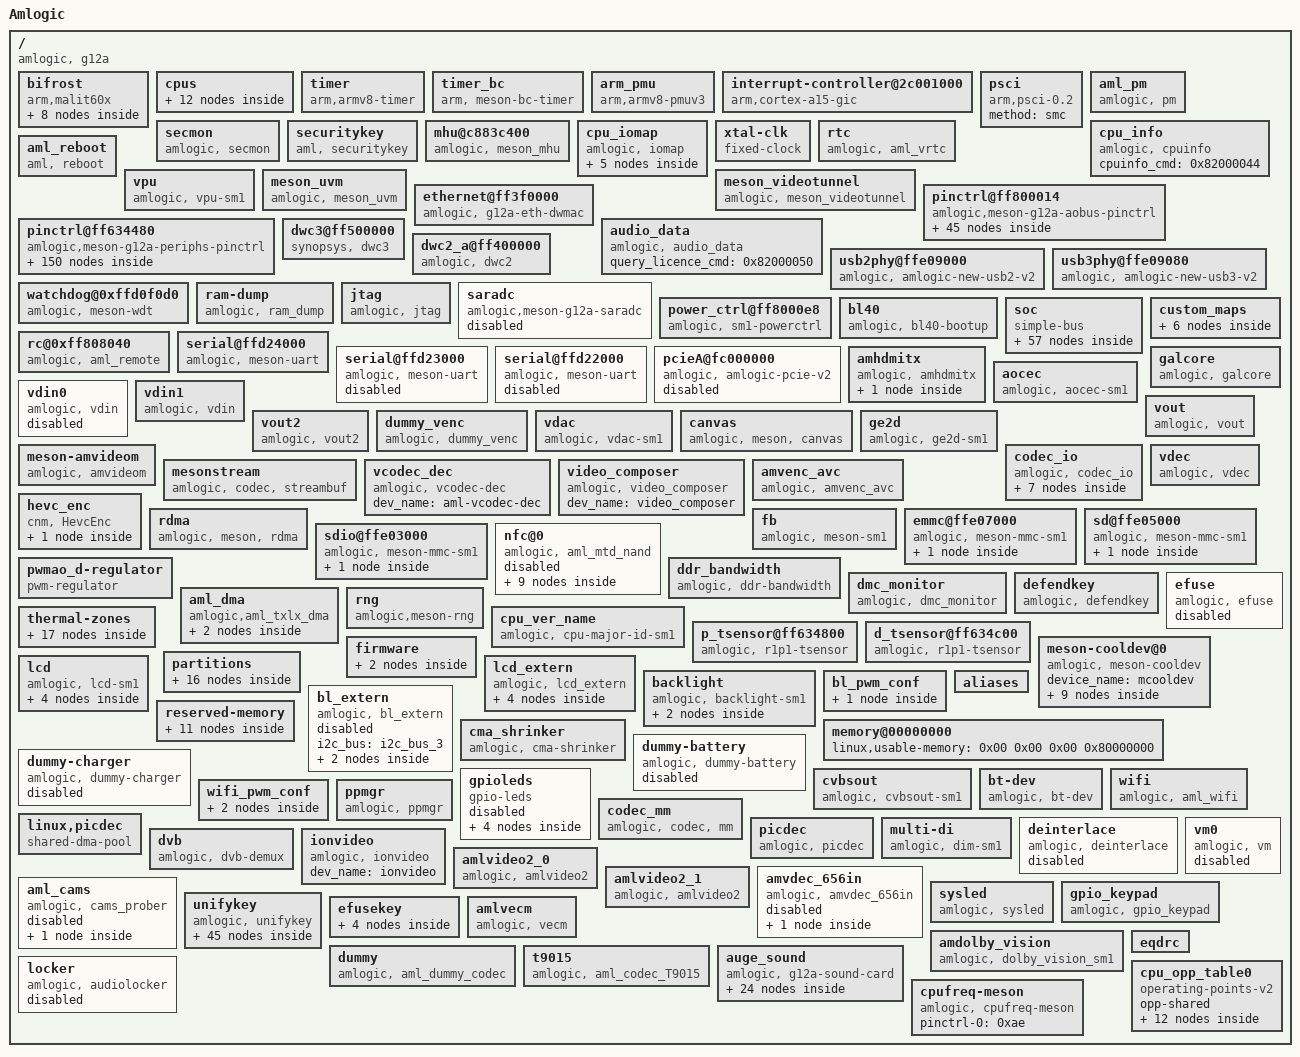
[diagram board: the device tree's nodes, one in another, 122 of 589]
/dts-v1/;

/ {
	model = "Amlogic";
	amlogic-dt-id = "sm1_ac214_2g";
	compatible = "amlogic, g12a";
	interrupt-parent = <0x01>;
	#address-cells = <0x02>;
	#size-cells = <0x02>;

	bifrost {
		compatible = "arm,malit60x\0arm,malit6xx\0arm,mali-midgard";
		#cooling-cells = <0x02>;
		reg = <0x00 0xffe40000 0x00 0x4000 0x00 0xffd01000 0x00 0x1000 0x00 0xff800000 0x00 0x1000 0x00 0xff63c000 0x00 0x1000 0x00 0xffd01000 0x00 0x1000>;
		interrupt-parent = <0x01>;
		interrupts = <0x00 0xa0 0x04 0x00 0xa1 0x04 0x00 0xa2 0x04>;
		interrupt-names = "GPU\0MMU\0JOB";
		num_of_pp = <0x02>;
		sc_mpp = <0x01>;
		clocks = <0x02 0x83 0x02 0x07>;
		clock-names = "gpu_mux\0gp0_pll";
		tbl = <0x03 0x04 0x05 0x06 0x07 0x07>;
		phandle = <0xaf>;

		clk125_cfg {
			clk_freq = <0x7735940>;
			clk_parent = "fclk_div4";
			clkp_freq = <0x1dcd6500>;
			clk_reg = <0xa03>;
			voltage = <0x47e>;
			keep_count = <0x05>;
			threshold = <0x1e 0x78>;
			phandle = <0xb0>;
		};

		dvfs250_cfg {
			clk_freq = <0xee6b280>;
			clk_parent = "fclk_div4";
			clkp_freq = <0x1dcd6500>;
			clk_reg = <0xa01>;
			voltage = <0x47e>;
			keep_count = <0x05>;
			threshold = <0x50 0xaa>;
			phandle = <0xb1>;
		};

		dvfs285_cfg {
			clk_freq = <0x1107a76d>;
			clk_parent = "fclk_div7";
			clkp_freq = <0x1107a76d>;
			clk_reg = <0xe00>;
			voltage = <0x47e>;
			keep_count = <0x05>;
			threshold = <0x00 0x4c>;
			phandle = <0x03>;
		};

		dvfs400_cfg {
			clk_freq = <0x17d78400>;
			clk_parent = "fclk_div5";
			clkp_freq = <0x17d78400>;
			clk_reg = <0xc00>;
			voltage = <0x47e>;
			keep_count = <0x05>;
			threshold = <0x98 0xcf>;
			phandle = <0x04>;
		};

		dvfs500_cfg {
			clk_freq = <0x1dcd6500>;
			clk_parent = "fclk_div4";
			clkp_freq = <0x1dcd6500>;
			clk_reg = <0xa00>;
			voltage = <0x47e>;
			keep_count = <0x05>;
			threshold = <0x26 0xc2>;
			phandle = <0x05>;
		};

		dvfs666_cfg {
			clk_freq = <0x27bc86aa>;
			clk_parent = "fclk_div3";
			clkp_freq = <0x27bc86aa>;
			clk_reg = <0x800>;
			voltage = <0x47e>;
			keep_count = <0x05>;
			threshold = <0x96 0xcb>;
			phandle = <0x06>;
		};

		dvfs800_cfg {
			clk_freq = <0x2faf0800>;
			clk_parent = "fclk_div2p5";
			clkp_freq = <0x2faf0800>;
			clk_reg = <0x600>;
			voltage = <0x47e>;
			keep_count = <0x05>;
			threshold = <0xe6 0xff>;
			phandle = <0xb2>;
		};

		dvfs850_cfg {
			clk_freq = <0x326cef80>;
			clk_parent = "gp0_pll";
			clkp_freq = <0x326cef80>;
			clk_reg = <0x200>;
			voltage = <0x47e>;
			keep_count = <0x05>;
			threshold = <0x9c 0xff>;
			phandle = <0x07>;
		};
	};

	cpus {
		#address-cells = <0x02>;
		#size-cells = <0x00>;
		phandle = <0xb3>;

		cpu-map {

			cluster0 {
				phandle = <0xb4>;

				core0 {
					cpu = <0x08>;
				};

				core1 {
					cpu = <0x09>;
				};

				core2 {
					cpu = <0x0a>;
				};

				core3 {
					cpu = <0x0b>;
				};
			};
		};

		cpu@0 {
			device_type = "cpu";
			compatible = "arm,cortex-a53\0arm,armv8";
			reg = <0x00 0x00>;
			enable-method = "psci";
			cpu-idle-states = <0x0c>;
			clocks = <0x02 0x17 0x02 0x16 0x02 0x00 0x02 0xf8 0x02 0xf7>;
			clock-names = "core_clk\0low_freq_clk_parent\0high_freq_clk_parent\0dsu_clk\0dsu_pre_parent";
			operating-points-v2 = <0x0d>;
			cpu-supply = <0x0e>;
			voltage-tolerance = <0x00>;
			clock-latency = <0xc350>;
			phandle = <0x08>;
		};

		cpu@1 {
			device_type = "cpu";
			compatible = "arm,cortex-a53\0arm,armv8";
			reg = <0x00 0x01>;
			enable-method = "psci";
			cpu-idle-states = <0x0c>;
			clocks = <0x02 0x17 0x02 0x16 0x02 0x00 0x02 0xf8 0x02 0xf7>;
			clock-names = "core_clk\0low_freq_clk_parent\0high_freq_clk_parent\0dsu_clk\0dsu_pre_parent";
			operating-points-v2 = <0x0d>;
			cpu-supply = <0x0e>;
			voltage-tolerance = <0x00>;
			clock-latency = <0xc350>;
			phandle = <0x09>;
		};

		cpu@2 {
			device_type = "cpu";
			compatible = "arm,cortex-a53\0arm,armv8";
			reg = <0x00 0x02>;
			enable-method = "psci";
			cpu-idle-states = <0x0c>;
			clocks = <0x02 0x17 0x02 0x16 0x02 0x00 0x02 0xf8 0x02 0xf7>;
			clock-names = "core_clk\0low_freq_clk_parent\0high_freq_clk_parent\0dsu_clk\0dsu_pre_parent";
			operating-points-v2 = <0x0d>;
			cpu-supply = <0x0e>;
			voltage-tolerance = <0x00>;
			clock-latency = <0xc350>;
			phandle = <0x0a>;
		};

		cpu@3 {
			device_type = "cpu";
			compatible = "arm,cortex-a53\0arm,armv8";
			reg = <0x00 0x03>;
			enable-method = "psci";
			cpu-idle-states = <0x0c>;
			clocks = <0x02 0x17 0x02 0x16 0x02 0x00 0x02 0xf8 0x02 0xf7>;
			clock-names = "core_clk\0low_freq_clk_parent\0high_freq_clk_parent\0dsu_clk\0dsu_pre_parent";
			operating-points-v2 = <0x0d>;
			cpu-supply = <0x0e>;
			voltage-tolerance = <0x00>;
			clock-latency = <0xc350>;
			phandle = <0x0b>;
		};

		idle-states {
			entry-method = "arm,psci-0.2";

			cpu-sleep-0 {
				compatible = "arm,idle-state";
				arm,psci-suspend-param = <0x10000>;
				local-timer-stop;
				entry-latency-us = <0xfa0>;
				exit-latency-us = <0x1388>;
				min-residency-us = <0x2710>;
				phandle = <0x0c>;
			};
		};
	};

	timer {
		compatible = "arm,armv8-timer";
		interrupts = <0x01 0x0d 0xff08 0x01 0x0e 0xff08 0x01 0x0b 0xff08 0x01 0x0a 0xff08>;
	};

	timer_bc {
		compatible = "arm, meson-bc-timer";
		reg = <0x00 0xffd0f190 0x00 0x04 0x00 0xffd0f194 0x00 0x04>;
		timer_name = "Meson TimerF";
		clockevent-rating = <0x12c>;
		clockevent-shift = <0x14>;
		clockevent-features = <0x23>;
		interrupts = <0x00 0x3c 0x01>;
		bit_enable = <0x10>;
		bit_mode = <0x0c>;
		bit_resolution = <0x00>;
	};

	arm_pmu {
		compatible = "arm,armv8-pmuv3";
		interrupts = <0x00 0x89 0x04>;
		reg = <0x00 0xff634680 0x00 0x04>;
		cpumasks = <0x0f>;
		relax-timer-ns = <0x989680>;
		max-wait-cnt = <0x2710>;
	};

	interrupt-controller@2c001000 {
		compatible = "arm,cortex-a15-gic\0arm,cortex-a9-gic";
		#interrupt-cells = <0x03>;
		#address-cells = <0x00>;
		interrupt-controller;
		reg = <0x00 0xffc01000 0x00 0x1000 0x00 0xffc02000 0x00 0x100>;
		interrupts = <0x01 0x09 0xf04>;
		phandle = <0x01>;
	};

	psci {
		compatible = "arm,psci-0.2";
		method = "smc";
	};

	aml_pm {
		compatible = "amlogic, pm";
		status = "okay";
		device_name = "aml_pm";
		debug_reg = <0xff8000a8>;
		exit_reg = <0xff80023c>;
	};

	secmon {
		compatible = "amlogic, secmon";
		memory-region = <0x0f>;
		in_base_func = <0x82000020>;
		out_base_func = <0x82000021>;
		reserve_mem_size = <0x300000>;
	};

	securitykey {
		compatible = "aml, securitykey";
		storage_query = <0x82000060>;
		storage_read = <0x82000061>;
		storage_write = <0x82000062>;
		storage_tell = <0x82000063>;
		storage_verify = <0x82000064>;
		storage_status = <0x82000065>;
		storage_list = <0x82000067>;
		storage_remove = <0x82000068>;
		storage_in_func = <0x82000023>;
		storage_out_func = <0x82000024>;
		storage_block_func = <0x82000025>;
		storage_size_func = <0x82000027>;
		storage_set_enctype = <0x8200006a>;
		storage_get_enctype = <0x8200006b>;
		storage_version = <0x8200006c>;
	};

	mhu@c883c400 {
		compatible = "amlogic, meson_mhu";
		reg = <0x00 0xff63c400 0x00 0x4c 0x00 0xfffe7000 0x00 0x800>;
		interrupts = <0x00 0xd1 0x01 0x00 0xd2 0x01 0x00 0xd5 0x01>;
		#mbox-cells = <0x01>;
		mbox-names = "cpu_to_scp_low\0bl4_to_cpu\0cpu_to_bl4";
		mboxes = <0x10 0x00 0x10 0x01 0x10 0x02>;
		num-chans-to-scp = <0x01>;
		send-isr-bits = <0x05>;
		ack-isr-bits = <0x04>;
		m4-isr-bits = <0x06>;
		mbox-chans = <0x03>;
		phandle = <0x10>;
	};

	cpu_iomap {
		compatible = "amlogic, iomap";
		#address-cells = <0x02>;
		#size-cells = <0x02>;
		ranges;

		io_cbus_base {
			reg = <0x00 0xffd00000 0x00 0x26fff>;
		};

		io_apb_base {
			reg = <0x00 0xffe01000 0x00 0x7f000>;
		};

		io_aobus_base {
			reg = <0x00 0xff800000 0x00 0xb000>;
		};

		io_vapb_base {
			reg = <0x00 0xff900000 0x00 0x50000>;
		};

		io_hiu_base {
			reg = <0x00 0xff63c000 0x00 0x2000>;
		};
	};

	xtal-clk {
		compatible = "fixed-clock";
		clock-frequency = <0x16e3600>;
		clock-output-names = "xtal";
		#clock-cells = <0x00>;
		phandle = <0x14>;
	};

	rtc {
		compatible = "amlogic, aml_vrtc";
		alarm_reg_addr = <0xff8000a8>;
		timer_e_addr = <0xffd0f188>;
		init_date = "2015/01/01";
		status = "okay";
	};

	cpu_info {
		compatible = "amlogic, cpuinfo";
		status = "okay";
		cpuinfo_cmd = <0x82000044>;
	};

	aml_reboot {
		compatible = "aml, reboot";
		sys_reset = <0x84000009>;
		sys_poweroff = <0x84000008>;
	};

	vpu {
		compatible = "amlogic, vpu-sm1";
		dev_name = "vpu";
		status = "okay";
		clocks = <0x02 0x95 0x02 0x4c 0x02 0x87 0x02 0x8b 0x02 0x8c>;
		clock-names = "vapb_clk\0vpu_intr_gate\0vpu_clk0\0vpu_clk1\0vpu_clk";
		clk_level = <0x07>;
		phandle = <0xb5>;
	};

	meson_uvm {
		compatible = "amlogic, meson_uvm";
		status = "okay";
	};

	meson_videotunnel {
		compatible = "amlogic, meson_videotunnel";
		status = "okay";
	};

	ethernet@ff3f0000 {
		compatible = "amlogic, g12a-eth-dwmac\0snps,dwmac";
		reg = <0x00 0xff3f0000 0x00 0x10000 0x00 0xff634540 0x00 0x08 0x00 0xff64c000 0x00 0xa0 0x00 0xffd01008 0x00 0x04>;
		reg-names = "eth_base\0eth_cfg\0eth_pll\0eth_reset";
		interrupts = <0x00 0x08 0x01>;
		interrupt-names = "macirq";
		status = "okay";
		clocks = <0x02 0x38>;
		clock-names = "ethclk81";
		pll_val = <0x9c0040a 0x927e0000 0xac5f49e5>;
		analog_val = <0x20200000 0xc000 0x23>;
		pinctrl-names = "internal_eth_pins";
		pinctrl-0 = <0x11>;
		mc_val = <0x4be04>;
		internal_phy = <0x01>;
		phandle = <0xb6>;
	};

	pinctrl@ff800014 {
		compatible = "amlogic,meson-g12a-aobus-pinctrl";
		#address-cells = <0x02>;
		#size-cells = <0x02>;
		ranges;
		phandle = <0xb7>;

		ao-bank@ff800014 {
			reg = <0x00 0xff800014 0x00 0x08 0x00 0xff800024 0x00 0x14 0x00 0xff80001c 0x00 0x08>;
			reg-names = "mux\0gpio\0drive-strength";
			gpio-controller;
			#gpio-cells = <0x02>;
			phandle = <0x66>;
		};

		sd_to_ao_uart_clr_pins {
			phandle = <0x3f>;

			mux {
				groups = "GPIOAO_0\0GPIOAO_1";
				function = "gpio_aobus";
			};
		};

		sd_to_ao_uart_pins {
			phandle = <0x41>;

			mux {
				groups = "uart_ao_tx_a\0uart_ao_rx_a";
				function = "uart_ao_a";
				bias-pull-up;
				input-enable;
			};
		};

		ao_uart {
			phandle = <0xb8>;

			mux {
				groups = "uart_ao_tx_a\0uart_ao_rx_a";
				function = "uart_ao_a";
			};
		};

		ao_b_uart {
			phandle = <0x1b>;

			mux {
				groups = "uart_ao_tx_b_2\0uart_ao_rx_b_3";
				function = "uart_ao_b";
			};
		};

		ao_i2c_pins1 {
			phandle = <0xb9>;

			mux {
				groups = "i2c_ao_sck\0i2c_ao_sda";
				function = "i2c_ao";
				drive-strength = <0x02>;
			};
		};

		ao_i2c_pins2 {
			phandle = <0xba>;

			mux {
				groups = "i2c_ao_sck_e\0i2c_ao_sda_e";
				function = "i2c_ao";
				drive-strength = <0x02>;
			};
		};

		ao_i2c_slave_pins {
			phandle = <0x1a>;

			mux {
				groups = "i2c_ao_slave_sck\0i2c_ao_slave_sda";
				function = "i2c_ao_slave";
			};
		};

		pwm_ao_a {
			phandle = <0xbb>;

			mux {
				groups = "pwm_ao_a";
				function = "pwm_ao_a";
			};
		};

		pwm_ao_a_hiz {
			phandle = <0xbc>;

			mux {
				groups = "pwm_ao_a_hiz";
				function = "pwm_ao_a";
			};
		};

		pwm_ao_b {
			phandle = <0xbd>;

			mux {
				groups = "pwm_ao_b";
				function = "pwm_ao_b";
			};
		};

		pwm_ao_c_pins1 {
			phandle = <0xbe>;

			mux {
				groups = "pwm_ao_c_4";
				function = "pwm_ao_c";
			};
		};

		pwm_ao_c_pins2 {
			phandle = <0xbf>;

			mux {
				groups = "pwm_ao_c_6";
				function = "pwm_ao_c";
			};
		};

		pwm_ao_c_hiz {
			phandle = <0xc0>;

			mux {
				groups = "pwm_ao_c_hiz_4";
				function = "pwm_ao_c";
			};
		};

		pwm_ao_d_pins1 {
			phandle = <0xc1>;

			mux {
				groups = "pwm_ao_d_5";
				function = "pwm_ao_d";
			};
		};

		pwm_ao_d_pins2 {
			phandle = <0xc2>;

			mux {
				groups = "pwm_ao_d_10";
				function = "pwm_ao_d";
			};
		};

		pwm_ao_d_pins3 {
			phandle = <0xae>;

			mux {
				groups = "pwm_ao_d_e";
				function = "pwm_ao_d";
			};
		};

		ao_ceca {
			phandle = <0xc3>;

			mux {
				groups = "cec_ao_a";
				function = "cec_ao";
			};
		};

		ao_cecb {
			phandle = <0xc4>;

			mux {
				groups = "cec_ao_b";
				function = "cec_ao";
			};
		};

		jtag_apao_pin {
			phandle = <0x15>;

			mux {
				groups = "jtag_a_tdi\0jtag_a_tdo\0jtag_a_clk\0jtag_a_tms";
				function = "jtag_a";
			};
		};

		remote_pin {
			phandle = <0x25>;

			mux {
				groups = "remote_input_ao";
				function = "remote_input_ao";
			};
		};

		irblaster_pin {
			phandle = <0xc5>;

			mux {
				groups = "remote_out_ao";
				function = "remote_out_ao";
			};
		};

		dvb_s_ts0_pins {
			phandle = <0xc6>;

			tsin_a {
				groups = "tsin_a_sop_ao\0tsin_a_valid_ao\0tsin_a_clk_ao\0tsin_a_din0_ao";
				function = "tsin_a_ao";
			};
		};
	};

	pinctrl@ff634480 {
		compatible = "amlogic,meson-g12a-periphs-pinctrl";
		#address-cells = <0x02>;
		#size-cells = <0x02>;
		ranges;
		phandle = <0xc7>;

		banks@ff6346c0 {
			reg = <0x00 0xff6346c0 0x00 0x40 0x00 0xff6344e8 0x00 0x18 0x00 0xff634520 0x00 0x18 0x00 0xff634440 0x00 0x4c 0x00 0xff634740 0x00 0x1c>;
			reg-names = "mux\0pull\0pull-enable\0gpio\0drive-strength";
			gpio-controller;
			#gpio-cells = <0x02>;
			phandle = <0x18>;
		};

		emmc_clk_cmd_pins {
			phandle = <0x39>;

			mux {
				groups = "emmc_clk\0emmc_cmd";
				function = "emmc";
				input-enable;
				bias-pull-up;
				drive-strength = <0x03>;
			};
		};

		emmc_conf_pull_up {
			phandle = <0x3a>;

			mux {
				groups = "emmc_nand_d7\0emmc_nand_d6\0emmc_nand_d5\0emmc_nand_d4\0emmc_nand_d3\0emmc_nand_d2\0emmc_nand_d1\0emmc_nand_d0\0emmc_clk\0emmc_cmd";
				function = "emmc";
				input-enable;
				bias-pull-up;
				drive-strength = <0x03>;
			};
		};

		emmc_conf_pull_done {
			phandle = <0x3b>;

			mux {
				groups = "emmc_nand_ds";
				function = "emmc";
				input-enable;
				bias-pull-down;
				drive-strength = <0x03>;
			};
		};

		sd_clk_cmd_pins {
			phandle = <0x3d>;

			mux {
				groups = "sdcard_cmd_c";
				function = "sdcard";
				input-enable;
				bias-pull-up;
				drive-strength = <0x03>;
			};

			mux1 {
				groups = "sdcard_clk_c";
				function = "sdcard";
				bias-pull-up;
				output-high;
				drive-strength = <0x03>;
			};
		};

		sd_all_pins {
			phandle = <0x3c>;

			mux {
				groups = "sdcard_d0_c\0sdcard_d1_c\0sdcard_d2_c\0sdcard_d3_c\0sdcard_cmd_c";
				function = "sdcard";
				input-enable;
				bias-pull-up;
				drive-strength = <0x03>;
			};

			mux1 {
				groups = "sdcard_clk_c";
				function = "sdcard";
				bias-pull-up;
				output-high;
				drive-strength = <0x03>;
			};
		};

		sd_all_pd_pins {
			phandle = <0x42>;

			mux {
				groups = "GPIOC_0\0GPIOC_1\0GPIOC_2\0GPIOC_3\0GPIOC_4\0GPIOC_5";
				function = "gpio_periphs";
				bias-pull-down;
				output-low;
			};
		};

		sd_1bit_pins {
			phandle = <0x3e>;

			mux {
				groups = "sdcard_d0_c\0sdcard_cmd_c";
				function = "sdcard";
				input-enable;
				bias-pull-up;
				drive-strength = <0x03>;
			};

			mux1 {
				groups = "sdcard_clk_c";
				function = "sdcard";
				bias-pull-up;
				output-high;
				drive-strength = <0x03>;
			};
		};

		sd_clr_all_pins {
			phandle = <0xc8>;

			mux {
				groups = "GPIOC_0\0GPIOC_1\0GPIOC_2\0GPIOC_3\0GPIOC_5";
				function = "gpio_periphs";
				output-high;
			};

			mux1 {
				groups = "GPIOC_4";
				function = "gpio_periphs";
				output-low;
			};
		};

		sd_clr_noall_pins {
			phandle = <0xc9>;

			mux {
				groups = "GPIOC_0\0GPIOC_1\0GPIOC_4\0GPIOC_5";
				function = "gpio_periphs";
				output-high;
			};
		};

		ao_to_sd_uart_pins {
			phandle = <0x40>;

			mux {
				groups = "uart_ao_tx_a_c3\0uart_ao_rx_a_c2";
				function = "uart_ao_a_ee";
				bias-pull-up;
				input-enable;
			};
		};

		sdio_clk_cmd_pins {
			phandle = <0x44>;

			mux {
				groups = "sdio_clk\0sdio_cmd";
				function = "sdio";
				input-enable;
				bias-pull-up;
				drive-strength = <0x03>;
			};
		};

		sdio_all_pins {
			phandle = <0x43>;

			mux {
				groups = "sdio_d0\0sdio_d1\0sdio_d2\0sdio_d3\0sdio_clk\0sdio_cmd";
				function = "sdio";
				input-enable;
				bias-pull-up;
				drive-strength = <0x03>;
			};
		};

		sdio_x_clk_cmd_pins {
			phandle = <0xca>;

			mux {
				groups = "GPIOX_5";
				function = "gpio_periphs";
				input-enable;
				bias-pull-up;
				drive-strength = <0x03>;
			};

			mux1 {
				groups = "GPIOX_4";
				function = "gpio_periphs";
				bias-pull-up;
				output-high;
				drive-strength = <0x03>;
			};
		};

		sdio_x_all_pins {
			phandle = <0xcb>;

			mux {
				groups = "GPIOX_0\0GPIOX_1\0GPIOX_2\0GPIOX_3\0GPIOX_5";
				function = "gpio_periphs";
				input-enable;
				bias-pull-up;
				drive-strength = <0x03>;
			};

			mux1 {
				groups = "GPIOX_4";
				function = "gpio_periphs";
				bias-pull-up;
				output-high;
				drive-strength = <0x03>;
			};
		};

		sdio_x_en_pins {
			phandle = <0xcc>;

			mux {
				groups = "sdio_dummy";
				function = "sdio";
				bias-pull-up;
				output-high;
			};
		};

		sdio_x_clr_pins {
			phandle = <0xcd>;

			mux {
				groups = "GPIOV_0";
				function = "gpio_periphs";
				bias-pull-up;
				output-low;
			};

			mux1 {
				groups = "GPIOX_4";
				function = "gpio_periphs";
				output-low;
			};
		};

		all_nand_pins {
			phandle = <0x45>;

			mux {
				groups = "emmc_nand_d0\0emmc_nand_d1\0emmc_nand_d2\0emmc_nand_d3\0emmc_nand_d4\0emmc_nand_d5\0emmc_nand_d6\0emmc_nand_d7\0nand_ce0\0nand_ale\0nand_cle\0nand_wen_clk\0nand_ren_wr\0nand_rb0";
				function = "nand";
				input-enable;
			};
		};

		nand_cs {
			phandle = <0x46>;

			mux {
				groups = "nand_ce0";
				function = "nand";
			};
		};

		i2c0_pins1 {
			phandle = <0xce>;

			mux {
				groups = "i2c0_sda_c\0i2c0_sck_c";
				function = "i2c0";
				drive-strength = <0x02>;
			};
		};

		i2c0_pins2 {
			phandle = <0x17>;

			mux {
				groups = "i2c0_sda_z0\0i2c0_sck_z1";
				function = "i2c0";
				drive-strength = <0x02>;
			};
		};

		i2c0_pins3 {
			phandle = <0xcf>;

			mux {
				groups = "i2c0_sda_z7\0i2c0_sck_z8";
				function = "i2c0";
				drive-strength = <0x02>;
			};
		};

		i2c1_pins1 {
			phandle = <0xd0>;

			mux {
				groups = "i2c1_sda_x\0i2c1_sck_x";
				function = "i2c1";
				drive-strength = <0x02>;
			};
		};

		i2c1_pins2 {
			phandle = <0xd1>;

			mux {
				groups = "i2c1_sda_h2\0i2c1_sck_h3";
				function = "i2c1";
				drive-strength = <0x02>;
			};
		};

		i2c1_pins3 {
			phandle = <0xd2>;

			mux {
				groups = "i2c1_sda_h6\0i2c1_sck_h7";
				function = "i2c1";
				drive-strength = <0x02>;
			};
		};

		i2c2_pins1 {
			phandle = <0xd3>;

			mux {
				groups = "i2c2_sda_x\0i2c2_sck_x";
				function = "i2c2";
				drive-strength = <0x02>;
			};
		};

		i2c2_pins2 {
			phandle = <0xd4>;

			mux {
				groups = "i2c2_sda_z\0i2c2_sck_z";
				function = "i2c2";
				drive-strength = <0x02>;
			};
		};

		i2c2_pins3 {
			phandle = <0xd5>;

			mux {
				groups = "i2c2_sda_z10\0i2c2_sck_z11";
				function = "i2c2";
				drive-strength = <0x02>;
			};
		};

		i2c3_pins1 {
			phandle = <0x34>;

			mux {
				groups = "i2c3_sda_h\0i2c3_sck_h";
				function = "i2c3";
				drive-strength = <0x02>;
			};
		};

		i2c3_pins2 {
			phandle = <0x19>;

			mux {
				groups = "i2c3_sda_a\0i2c3_sck_a";
				function = "i2c3";
				drive-strength = <0x02>;
			};
		};

		pwm_a {
			phandle = <0xd6>;

			mux {
				groups = "pwm_a";
				function = "pwm_a";
			};
		};

		pwm_b_pins1 {
			phandle = <0xd7>;

			mux {
				groups = "pwm_b_x7";
				function = "pwm_b";
			};
		};

		pwm_b_pins2 {
			phandle = <0xd8>;

			mux {
				groups = "pwm_b_x19";
				function = "pwm_b";
			};
		};

		pwm_c_pins1 {
			phandle = <0xd9>;

			mux {
				groups = "pwm_c_c4";
				function = "pwm_c";
			};
		};

		pwm_c_pins2 {
			phandle = <0xda>;

			mux {
				groups = "pwm_c_x5";
				function = "pwm_c";
			};
		};

		pwm_c_pins3 {
			phandle = <0xdb>;

			mux {
				groups = "pwm_c_x8";
				function = "pwm_c";
			};
		};

		pwm_d_pins1 {
			phandle = <0xdc>;

			mux {
				groups = "pwm_d_x3";
				function = "pwm_d";
			};
		};

		pwm_d_pins2 {
			phandle = <0xdd>;

			mux {
				groups = "pwm_d_x6";
				function = "pwm_d";
			};
		};

		pwm_e {
			phandle = <0x67>;

			mux {
				groups = "pwm_e";
				function = "pwm_e";
				drive-strength = <0x00>;
			};
		};

		pwm_f_pins1 {
			phandle = <0xde>;

			mux {
				groups = "pwm_f_x";
				function = "pwm_f";
			};
		};

		pwm_f_pins2 {
			phandle = <0x63>;

			mux {
				groups = "pwm_f_h";
				function = "pwm_f";
			};
		};

		spicc0_pins_x {
			phandle = <0xdf>;

			mux {
				groups = "spi0_mosi_x\0spi0_miso_x\0spi0_clk_x";
				function = "spi0";
				drive-strength = <0x01>;
			};
		};

		spicc0_pins_c {
			phandle = <0xe0>;

			mux {
				groups = "spi0_mosi_c\0spi0_miso_c\0spi0_ss0_c\0spi0_clk_c";
				function = "spi0";
				drive-strength = <0x01>;
			};
		};

		spicc1_pins {
			phandle = <0xe1>;

			mux {
				groups = "spi1_mosi\0spi1_miso\0spi1_clk";
				function = "spi1";
				drive-strength = <0x01>;
			};
		};

		a_uart {
			phandle = <0x2d>;

			mux {
				groups = "uart_tx_a\0uart_rx_a\0uart_cts_a\0uart_rts_a";
				function = "uart_a";
			};
		};

		b_uart {
			phandle = <0x2e>;

			mux {
				groups = "uart_tx_b\0uart_rx_b";
				function = "uart_b";
			};
		};

		c_uart {
			phandle = <0x2f>;

			mux {
				groups = "uart_tx_c\0uart_rx_c";
				function = "uart_c";
			};
		};

		hdmitx_hpd {
			phandle = <0x31>;

			mux {
				groups = "hdmitx_hpd_in";
				function = "hdmitx";
				bias-disable;
			};
		};

		hdmitx_hpd_gpio {
			phandle = <0x33>;

			mux {
				groups = "GPIOH_1";
				function = "gpio_periphs";
				bias-disable;
			};
		};

		hdmitx_ddc {
			phandle = <0x32>;

			mux {
				groups = "hdmitx_sda\0hdmitx_sck";
				function = "hdmitx";
				bias-disable;
				drive-strength = <0x03>;
			};
		};

		ee_ceca {
			phandle = <0x35>;

			mux {
				groups = "cec_ao_a_ee";
				function = "cec_ao_ee";
			};
		};

		ee_cecb {
			phandle = <0x36>;

			mux {
				groups = "cec_ao_b_ee";
				function = "cec_ao_ee";
			};
		};

		internal_eth_pins {
			phandle = <0x11>;

			mux {
				groups = "eth_link_led\0eth_act_led";
				function = "eth";
			};
		};

		internal_gpio_pins {
			phandle = <0xe2>;

			mux {
				groups = "GPIOZ_14\0GPIOZ_15";
				function = "gpio_periphs";
				bias-disable;
				input-enable;
			};
		};

		external_eth_pins {
			phandle = <0xe3>;

			mux {
				groups = "eth_mdio\0eth_mdc\0eth_rgmii_rx_clk\0eth_rx_dv\0eth_rxd0\0eth_rxd1\0eth_rxd2_rgmii\0eth_rxd3_rgmii\0eth_rgmii_tx_clk\0eth_txen\0eth_txd0\0eth_txd1\0eth_txd2_rgmii\0eth_txd3_rgmii";
				function = "eth";
				drive-strength = <0x03>;
			};
		};

		jtag_apee_pin {
			phandle = <0x16>;

			mux {
				groups = "jtag_b_tdi\0jtag_b_tdo\0jtag_b_clk\0jtag_b_tms";
				function = "jtag_b";
			};
		};

		tdmout_a {
			phandle = <0x1e>;

			mux {
				groups = "tdma_sclk\0tdma_fs\0tdma_dout0";
				function = "tdma_out";
			};
		};

		tdmin_a {
			phandle = <0x1f>;

			mux {
				groups = "tdma_din1";
				function = "tdma_in";
			};
		};

		tdmb_mclk {
			phandle = <0x20>;

			mux {
				groups = "mclk0_a";
				function = "mclk0";
				drive-strength = <0x02>;
			};
		};

		tdmout_b {
			phandle = <0x21>;

			mux {
				groups = "tdmb_sclk\0tdmb_fs\0tdmb_dout0";
				function = "tdmb_out";
				drive-strength = <0x02>;
			};
		};

		tdmin_b {
			phandle = <0x22>;

			mux {
				groups = "tdmb_din1";
				function = "tdmb_in";
				drive-strength = <0x02>;
			};
		};

		tdmc_mclk {
			phandle = <0xe4>;

			mux {
				groups = "mclk1_a";
				function = "mclk1";
			};
		};

		tdmout_c {
			phandle = <0xe5>;

			mux {
				groups = "tdmc_sclk_a\0tdmc_fs_a";
				function = "tdmc_out";
			};
		};

		tdmin_c {
			phandle = <0xe6>;

			mux {
				groups = "tdmc_din0_a";
				function = "tdmc_in";
			};
		};

		spdifin {
			phandle = <0xe7>;

			mux {
				groups = "spdif_in_h";
				function = "spdif_in";
			};
		};

		pdmin {
			phandle = <0x24>;

			mux {
				groups = "pdm_dclk_z";
				function = "pdm";
			};
		};

		bl_pwm_off_pin {
			phandle = <0xe8>;

			mux {
				pins = "GPIOH_5";
				function = "gpio_periphs";
				output-high;
			};
		};

		clk12_24_z_pins {
			phandle = <0xe9>;

			mux {
				groups = "clk12_24_z";
				function = "clk12_24_ee";
				drive-strength = <0x03>;
			};
		};

		gen_clk_ee_z {
			phandle = <0x71>;

			mux {
				groups = "gen_clk_ee_z";
				function = "gen_clk_ee";
				drive-strength = <0x03>;
			};
		};

		cam_dvp_pins {
			phandle = <0x70>;

			mux {
				groups = "bt656_a_vs\0bt656_a_hs\0bt656_a_clk\0bt656_a_din0\0bt656_a_din1\0bt656_a_din2\0bt656_a_din3\0bt656_a_din4\0bt656_a_din5\0bt656_a_din6\0bt656_a_din7";
				function = "bt656";
			};
		};

		spdifout {
			phandle = <0x23>;

			mux {
				groups = "spdif_out_h";
				function = "spdif_out";
			};
		};

		dvb_s_ts1_pins {
			phandle = <0xea>;

			tsin_b {
				groups = "tsin_b_clk_z\0tsin_b_din0_z\0tsin_b_sop_z\0tsin_b_valid_z";
				function = "tsin_b";
			};
		};
	};

	audio_data {
		compatible = "amlogic, audio_data";
		query_licence_cmd = <0x82000050>;
		status = "okay";
		phandle = <0xeb>;
	};

	dwc3@ff500000 {
		compatible = "synopsys, dwc3";
		status = "okay";
		reg = <0x00 0xff500000 0x00 0x100000>;
		interrupts = <0x00 0x1e 0x04>;
		usb-phy = <0x12 0x13>;
		cpu-type = "gxl";
		clock-src = "usb3.0";
		clocks = <0x02 0x41>;
		clock-names = "dwc_general";
		phandle = <0xec>;
	};

	usb2phy@ffe09000 {
		compatible = "amlogic, amlogic-new-usb2-v2";
		status = "okay";
		reg = <0x00 0xffe09000 0x00 0x80 0x00 0xffd01008 0x00 0x100 0x00 0xff636000 0x00 0x2000 0x00 0xff63a000 0x00 0x2000>;
		pll-setting-1 = <0x9400414>;
		pll-setting-2 = <0x927e0000>;
		pll-setting-3 = <0xac5f69e5>;
		pll-setting-4 = <0xfe18>;
		pll-setting-5 = <0x8000fff>;
		pll-setting-6 = <0x78000>;
		pll-setting-7 = <0xe0004>;
		pll-setting-8 = <0xe000c>;
		version = <0x02>;
		pwr-ctl = <0x01>;
		u2-ctrl-sleep-shift = <0x11>;
		u2-hhi-mem-pd-shift = <0x1e>;
		u2-hhi-mem-pd-mask = <0x03>;
		u2-ctrl-iso-shift = <0x11>;
		portnum = <0x02>;
		phandle = <0x12>;
	};

	usb3phy@ffe09080 {
		compatible = "amlogic, amlogic-new-usb3-v2";
		status = "okay";
		reg = <0x00 0xffe09080 0x00 0x20 0x00 0xffd01008 0x00 0x100>;
		phy-reg = <0xff646000>;
		phy-reg-size = <0x2000>;
		usb2-phy-reg = <0xffe09000>;
		usb2-phy-reg-size = <0x80>;
		interrupts = <0x00 0x10 0x04>;
		clocks = <0x02 0x18>;
		clock-names = "pcie_refpll";
		pwr-ctl = <0x01>;
		u3-ctrl-sleep-shift = <0x12>;
		u3-hhi-mem-pd-shift = <0x1a>;
		u3-hhi-mem-pd-mask = <0x0f>;
		u3-ctrl-iso-shift = <0x12>;
		portnum = <0x01>;
		otg = <0x00>;
		phandle = <0x13>;
	};

	dwc2_a@ff400000 {
		compatible = "amlogic, dwc2";
		status = "okay";
		device_name = "dwc2_a";
		reg = <0x00 0xff400000 0x00 0x40000>;
		interrupts = <0x00 0x1f 0x04>;
		pl-periph-id = <0x00>;
		clock-src = "usb0";
		port-id = <0x00>;
		port-type = <0x02>;
		port-speed = <0x00>;
		port-config = <0x00>;
		port-dma = <0x00>;
		port-id-mode = <0x00>;
		usb-fifo = <0x2d8>;
		cpu-type = "v2";
		phy-reg = <0xffe09000>;
		phy-reg-size = <0xa0>;
		phy-interface = <0x02>;
		clocks = <0x02 0x41 0x02 0x49>;
		clock-names = "usb_general\0usb1";
		controller-type = <0x01>;
		phandle = <0xed>;
	};

	watchdog@0xffd0f0d0 {
		compatible = "amlogic, meson-wdt";
		status = "okay";
		default_timeout = <0x0a>;
		reset_watchdog_method = <0x01>;
		reset_watchdog_time = <0x02>;
		shutdown_timeout = <0x0a>;
		firmware_timeout = <0x06>;
		suspend_timeout = <0x06>;
		reg = <0x00 0xffd0f0d0 0x00 0x10>;
		clock-names = "xtal";
		clocks = <0x14>;
		phandle = <0xee>;
	};

	ram-dump {
		compatible = "amlogic, ram_dump";
		status = "okay";
		reg = <0x00 0xff6345e0 0x00 0x04>;
		reg-names = "PREG_STICKY_REG8";
		store_device = "data";
	};

	jtag {
		compatible = "amlogic, jtag";
		status = "okay";
		select = "disable";
		pinctrl-names = "jtag_apao_pins\0jtag_apee_pins";
		pinctrl-0 = <0x15>;
		pinctrl-1 = <0x16>;
	};

	saradc {
		compatible = "amlogic,meson-g12a-saradc";
		status = "disabled";
		#io-channel-cells = <0x01>;
		clocks = <0x14 0x02 0x105>;
		clock-names = "xtal\0saradc_clk";
		interrupts = <0x00 0xc8 0x01>;
		reg = <0x00 0xff809000 0x00 0x48>;
		phandle = <0xef>;
	};

	power_ctrl@ff8000e8 {
		compatible = "amlogic, sm1-powerctrl";
		reg = <0x00 0xff8000e8 0x00 0x10 0x00 0xff63c100 0x00 0x10>;
		phandle = <0xf0>;
	};

	bl40 {
		compatible = "amlogic, bl40-bootup";
		status = "okay";
		phandle = <0xf1>;
	};

	soc {
		compatible = "simple-bus";
		#address-cells = <0x02>;
		#size-cells = <0x02>;
		ranges;

		cbus@ffd00000 {
			compatible = "simple-bus";
			reg = <0x00 0xffd00000 0x00 0x26000>;
			#address-cells = <0x02>;
			#size-cells = <0x02>;
			ranges = <0x00 0x00 0x00 0xffd00000 0x00 0x26000>;
			phandle = <0xf2>;

			interrupt-controller@f080 {
				compatible = "amlogic,meson-gpio-intc\0amlogic,meson-sm1-gpio-intc";
				reg = <0x00 0xf080 0x00 0x10>;
				interrupt-controller;
				#interrupt-cells = <0x02>;
				amlogic,channel-interrupts = <0x40 0x41 0x42 0x43 0x44 0x45 0x46 0x47>;
				status = "okay";
				phandle = <0xf3>;
			};

			meson_clk_msr {
				compatible = "amlogic, sm1-measure";
				reg = <0x00 0x18004 0x00 0x04 0x00 0x1800c 0x00 0x04>;
				ringctrl = <0xff6345fc>;
			};

			pwm@1b000 {
				compatible = "amlogic,g12a-ee-pwm";
				reg = <0x00 0x1b000 0x00 0x20>;
				#pwm-cells = <0x03>;
				clocks = <0x14 0x14 0x14 0x14>;
				clock-names = "clkin0\0clkin1\0clkin2\0clkin3";
				status = "disabled";
				phandle = <0xf4>;
			};

			pwm@1a000 {
				compatible = "amlogic,g12a-ee-pwm";
				reg = <0x00 0x1a000 0x00 0x20>;
				#pwm-cells = <0x03>;
				clocks = <0x14 0x14 0x14 0x14>;
				clock-names = "clkin0\0clkin1\0clkin2\0clkin3";
				status = "disabled";
				phandle = <0xf5>;
			};

			pwm@19000 {
				compatible = "amlogic,g12a-ee-pwm";
				reg = <0x00 0x19000 0x00 0x20>;
				#pwm-cells = <0x03>;
				clocks = <0x14 0x14 0x14 0x14>;
				clock-names = "clkin0\0clkin1\0clkin2\0clkin3";
				status = "okay";
				phandle = <0x65>;
			};

			i2c@1f000 {
				compatible = "amlogic,meson-g12a-i2c";
				status = "okay";
				reg = <0x00 0x1f000 0x00 0x20>;
				interrupts = <0x00 0x15 0x01 0x00 0x5b 0x01>;
				#address-cells = <0x01>;
				#size-cells = <0x00>;
				clocks = <0x02 0x2a>;
				clock-names = "clk_i2c";
				pinctrl-names = "default";
				pinctrl-0 = <0x17>;
				clock-frequency = <0x61a80>;
				phandle = <0xf6>;

				gt9xx@5d {
					compatible = "goodix,gt9xx";
					status = "disabled";
					reg = <0x5d>;
					reset-gpio = <0x18 0x0a 0x00>;
					irq-gpio = <0x18 0x04 0x00>;
				};

				ftxx@38 {
					compatible = "focaltech,fts";
					status = "disabled";
					reg = <0x38>;
					reset-gpio = <0x18 0x0a 0x00>;
					irq-gpio = <0x18 0x04 0x00>;
					x_max = <0x258>;
					y_max = <0x400>;
					max-touch-number = <0x0a>;
				};
			};

			i2c@1e000 {
				compatible = "amlogic,meson-g12a-i2c";
				status = "disabled";
				reg = <0x00 0x1e000 0x00 0x20>;
				interrupts = <0x00 0xd6 0x01 0x00 0x5c 0x01>;
				#address-cells = <0x01>;
				#size-cells = <0x00>;
				clocks = <0x02 0x2a>;
				clock-names = "clk_i2c";
				phandle = <0xf7>;
			};

			i2c@1d000 {
				compatible = "amlogic,meson-g12a-i2c";
				status = "disabled";
				reg = <0x00 0x1d000 0x00 0x20>;
				interrupts = <0x00 0xd7 0x01 0x00 0x5e 0x01>;
				#address-cells = <0x01>;
				#size-cells = <0x00>;
				clocks = <0x02 0x2a>;
				clock-names = "clk_i2c";
				phandle = <0x72>;
			};

			i2c@1c000 {
				compatible = "amlogic,meson-g12a-i2c";
				status = "okay";
				reg = <0x00 0x1c000 0x00 0x20>;
				interrupts = <0x00 0x27 0x01 0x00 0x5f 0x01>;
				#address-cells = <0x01>;
				#size-cells = <0x00>;
				clocks = <0x02 0x2a>;
				clock-names = "clk_i2c";
				pinctrl-names = "default";
				pinctrl-0 = <0x19>;
				clock-frequency = <0x493e0>;
				phandle = <0x6e>;

				ad82584f_62@62 {
					compatible = "ESMT, ad82584f";
					#sound-dai-cells = <0x00>;
					reg = <0x31>;
					status = "disabled";
					reset_pin = <0x18 0x37 0x00>;
					no_mclk;
					phandle = <0xf8>;
				};

				bl_extern_i2c {
					compatible = "bl_extern, i2c";
					dev_name = "lp8556";
					reg = <0x2c>;
					status = "disabled";
				};
			};

			spi@13000 {
				compatible = "amlogic,meson-g12a-spicc";
				reg = <0x00 0x13000 0x00 0x44>;
				interrupts = <0x00 0x51 0x04>;
				clocks = <0x02 0x29 0x02 0xd1>;
				clock-names = "core\0comp";
				#address-cells = <0x01>;
				#size-cells = <0x00>;
				status = "disabled";
				phandle = <0xf9>;
			};

			spi@15000 {
				compatible = "amlogic,meson-g12a-spicc";
				reg = <0x00 0x15000 0x00 0x44>;
				interrupts = <0x00 0x5a 0x04>;
				clocks = <0x02 0x2f 0x02 0xd5>;
				clock-names = "core\0comp";
				#address-cells = <0x01>;
				#size-cells = <0x00>;
				status = "disabled";
				phandle = <0xfa>;
			};
		};

		aobus@ff800000 {
			compatible = "simple-bus";
			reg = <0x00 0xff800000 0x00 0xb000>;
			#address-cells = <0x02>;
			#size-cells = <0x02>;
			ranges = <0x00 0x00 0x00 0xff800000 0x00 0xb000>;
			phandle = <0xfb>;

			cpu_version {
				reg = <0x00 0x220 0x00 0x04>;
			};

			clock-controller@0 {
				compatible = "amlogic,sm1-aoclkc";
				#clock-cells = <0x01>;
				#reset-cells = <0x01>;
				reg = <0x00 0x00 0x00 0x3dc>;
				phandle = <0xfc>;
			};

			pwm@7000 {
				compatible = "amlogic,g12a-ao-pwm";
				reg = <0x00 0x7000 0x00 0x20>;
				#pwm-cells = <0x03>;
				clocks = <0x14 0x14 0x14 0x14>;
				clock-names = "clkin0\0clkin1\0clkin2\0clkin3";
				status = "disabled";
				phandle = <0xfd>;
			};

			pwm@2000 {
				compatible = "amlogic,g12a-ao-pwm";
				reg = <0x00 0x2000 0x00 0x20>;
				#pwm-cells = <0x03>;
				clocks = <0x14 0x14 0x14 0x14>;
				clock-names = "clkin0\0clkin1\0clkin2\0clkin3";
				status = "okay";
				phandle = <0x4a>;
			};

			i2c@5000 {
				compatible = "amlogic,meson-g12a-i2c";
				status = "disabled";
				reg = <0x00 0x5000 0x00 0x20>;
				interrupts = <0x00 0xc3 0x01 0x00 0xc9 0x01>;
				#address-cells = <0x01>;
				#size-cells = <0x00>;
				clocks = <0x02 0x2a>;
				clock-names = "clk_i2c";
				phandle = <0xfe>;
			};

			i2c_slave@6000 {
				compatible = "amlogic, meson-i2c-slave";
				status = "disabled";
				reg = <0x00 0x6000 0x00 0x20>;
				interrupts = <0x00 0xc2 0x01>;
				pinctrl-names = "default";
				pinctrl-0 = <0x1a>;
				phandle = <0xff>;
			};

			serial@3000 {
				compatible = "amlogic, meson-uart";
				reg = <0x00 0x3000 0x00 0x18>;
				interrupts = <0x00 0xc1 0x01>;
				status = "okay";
				clocks = <0x14>;
				clock-names = "clk_uart";
				xtal_tick_en = <0x02>;
				fifosize = <0x40>;
				pinctrl-names = "default";
				support-sysrq = <0x01>;
				phandle = <0x100>;
			};

			serial@4000 {
				compatible = "amlogic, meson-uart";
				reg = <0x00 0x4000 0x00 0x18>;
				interrupts = <0x00 0xc5 0x01>;
				status = "disabled";
				clocks = <0x14>;
				clock-names = "clk_uart";
				fifosize = <0x40>;
				pinctrl-names = "default";
				pinctrl-0 = <0x1b>;
				phandle = <0x101>;
			};

			meson-irblaster@14c {
				compatible = "amlogic, meson_irblaster";
				reg = <0x00 0x14c 0x00 0x10 0x00 0x40 0x00 0x04>;
				#irblaster-cells = <0x02>;
				interrupts = <0x00 0xc6 0x01>;
				status = "okay";
				phandle = <0x102>;
			};
		};

		periphs@ff634400 {
			compatible = "simple-bus";
			reg = <0x00 0xff634400 0x00 0x400>;
			#address-cells = <0x02>;
			#size-cells = <0x02>;
			ranges = <0x00 0x00 0x00 0xff634400 0x00 0x400>;
			phandle = <0x103>;
		};

		hiubus@ff63c000 {
			compatible = "simple-bus";
			reg = <0x00 0xff63c000 0x00 0x2000>;
			#address-cells = <0x02>;
			#size-cells = <0x02>;
			ranges = <0x00 0x00 0x00 0xff63c000 0x00 0x2000>;
			phandle = <0x104>;

			clock-controller@0 {
				compatible = "amlogic,sm1-clkc-1";
				#clock-cells = <0x01>;
				reg = <0x00 0x00 0x00 0x3dc>;
				phandle = <0x02>;
			};

			clock-controller@1 {
				compatible = "amlogic,sm1-clkc-2";
				#clock-cells = <0x01>;
				reg = <0x00 0x00 0x00 0x3dc>;
				own-dsu-clk;
				clocks = <0x02 0x02>;
				clock-names = "clkin0";
				phandle = <0x105>;
			};
		};

		ion_dev {
			compatible = "amlogic, ion_dev";
			memory-region = <0x1c>;
		};

		audiobus@0xFF660000 {
			compatible = "amlogic, audio-controller\0simple-bus";
			reg = <0x00 0xff660000 0x00 0x3000>;
			#address-cells = <0x02>;
			#size-cells = <0x02>;
			ranges = <0x00 0x00 0x00 0xff660000 0x00 0x3000>;
			phandle = <0x106>;

			audio_clocks {
				compatible = "amlogic, sm1-audio-clocks";
				#clock-cells = <0x01>;
				reg = <0x00 0x00 0x00 0xb0>;
				phandle = <0x1d>;
			};

			ddr_manager {
				compatible = "amlogic, sm1-audio-ddr-manager";
				interrupts = <0x00 0x94 0x01 0x00 0x95 0x01 0x00 0x96 0x01 0x00 0x31 0x01 0x00 0x98 0x01 0x00 0x99 0x01 0x00 0x9a 0x01 0x00 0x32 0x01>;
				interrupt-names = "toddr_a\0toddr_b\0toddr_c\0toddr_d\0frddr_a\0frddr_b\0frddr_c\0frddr_d";
			};

			tdm@0 {
				compatible = "amlogic, sm1-snd-tdma";
				#sound-dai-cells = <0x00>;
				dai-tdm-lane-slot-mask-in = <0x00 0x01>;
				dai-tdm-oe-lane-slot-mask-out = <0x01 0x00>;
				dai-tdm-clk-sel = <0x00>;
				clocks = <0x1d 0x24 0x02 0x0c>;
				clock-names = "mclk\0clk_srcpll";
				pinctrl-names = "tdm_pins";
				pinctrl-0 = <0x1e 0x1f>;
				status = "okay";
				phandle = <0xa4>;
			};

			tdm@1 {
				compatible = "amlogic, sm1-snd-tdmb";
				#sound-dai-cells = <0x00>;
				dai-tdm-lane-slot-mask-in = <0x00 0x01 0x00 0x00>;
				dai-tdm-lane-slot-mask-out = <0x01 0x00 0x00 0x00>;
				dai-tdm-clk-sel = <0x01>;
				clocks = <0x1d 0x25 0x1d 0x3a 0x02 0x0d 0x02 0x0c 0x1d 0x2b>;
				clock-names = "mclk\0mclk_pad\0clk_srcpll\0samesource_srcpll\0samesource_clk";
				pinctrl-names = "tdm_pins";
				pinctrl-0 = <0x20 0x21 0x22>;
				samesource_sel = <0x03>;
				start_clk_enable = <0x01>;
				clk_tuning_enable = <0x01>;
				status = "okay";
				phandle = <0xa6>;
			};

			tdm@2 {
				compatible = "amlogic, sm1-snd-tdmc";
				#sound-dai-cells = <0x00>;
				dai-tdm-lane-slot-mask-out = <0x01 0x01 0x01 0x01>;
				dai-tdm-clk-sel = <0x02>;
				clocks = <0x1d 0x26 0x02 0x0e>;
				clock-names = "mclk\0clk_srcpll";
				i2s2hdmi = <0x01>;
				status = "okay";
				phandle = <0xa8>;
			};

			tdm@3 {
				compatible = "amlogic, sm1-snd-tdmlb";
				#sound-dai-cells = <0x00>;
				dai-tdm-lane-lb-slot-mask-in = <0x01 0x00 0x00 0x00>;
				dai-tdm-clk-sel = <0x01>;
				clocks = <0x1d 0x25 0x02 0x0d>;
				clock-names = "mclk\0clk_srcpll";
				lb-src-sel = <0x01>;
				status = "disabled";
				phandle = <0x107>;
			};

			spdif@0 {
				compatible = "amlogic, sm1-snd-spdif-a";
				#sound-dai-cells = <0x00>;
				clocks = <0x02 0x0c 0x02 0x04 0x1d 0x10 0x1d 0x11 0x1d 0x2a 0x1d 0x2b>;
				clock-names = "sysclk\0fixed_clk\0gate_spdifin\0gate_spdifout\0clk_spdifin\0clk_spdifout";
				interrupts = <0x00 0x97 0x01>;
				interrupt-names = "irq_spdifin";
				pinctrl-names = "spdif_pins";
				pinctrl-0 = <0x23>;
				clk_tuning_enable = <0x01>;
				status = "okay";
				phandle = <0xaa>;
			};

			spdif@1 {
				compatible = "amlogic, sm1-snd-spdif-b";
				#sound-dai-cells = <0x00>;
				clocks = <0x02 0x0e 0x1d 0x15 0x1d 0x31>;
				clock-names = "sysclk\0gate_spdifout\0clk_spdifout";
				status = "okay";
				phandle = <0xab>;
			};

			pdm {
				compatible = "amlogic, sm1-snd-pdm";
				#sound-dai-cells = <0x00>;
				clocks = <0x1d 0x01 0x02 0x03 0x02 0x0f 0x1d 0x2f 0x1d 0x30>;
				clock-names = "gate\0sysclk_srcpll\0dclk_srcpll\0pdm_dclk\0pdm_sysclk";
				pinctrl-names = "pdm_pins";
				pinctrl-0 = <0x24>;
				filter_mode = <0x01>;
				status = "okay";
				phandle = <0xa9>;
			};

			resample@0 {
				compatible = "amlogic, sm1-resample";
				clocks = <0x02 0x0f 0x1d 0x29 0x1d 0x2c>;
				clock-names = "resample_pll\0resample_src\0resample_clk";
				resample_module = <0x04>;
				status = "disabled";
				phandle = <0x108>;
			};

			vad {
				compatible = "amlogic, snd-vad";
				#sound-dai-cells = <0x00>;
				clocks = <0x1d 0x1b 0x02 0x05 0x1d 0x35>;
				clock-names = "gate\0pll\0clk";
				interrupts = <0x00 0x9b 0x01 0x00 0x30 0x01>;
				interrupt-names = "irq_wakeup\0irq_frame_sync";
				src = <0x04>;
				level = <0x01>;
				status = "okay";
				phandle = <0x109>;
			};

			loopback@0 {
				compatible = "amlogic, sm1-loopbacka";
				#sound-dai-cells = <0x00>;
				clocks = <0x1d 0x01 0x02 0x03 0x02 0x0f 0x1d 0x2f 0x1d 0x30 0x02 0x0c 0x1d 0x24>;
				clock-names = "pdm_gate\0pdm_sysclk_srcpll\0pdm_dclk_srcpll\0pdm_dclk\0pdm_sysclk\0tdminlb_mpll\0tdminlb_mclk";
				datain_src = <0x04>;
				datain_chnum = <0x02>;
				datain_chmask = <0x03>;
				datain-lane-mask-in = <0x01 0x00 0x00 0x00>;
				mclk-fs = <0x100>;
				datalb_src = <0x01>;
				datalb_chnum = <0x02>;
				datalb_chmask = <0x03>;
				datalb-lane-mask-in = <0x01 0x00 0x00 0x00>;
				status = "okay";
				phandle = <0xad>;
			};

			loopback@1 {
				compatible = "amlogic, sm1-loopbackb";
				#sound-dai-cells = <0x00>;
				clocks = <0x1d 0x01 0x02 0x03 0x02 0x0f 0x1d 0x2f 0x1d 0x30 0x02 0x0c 0x1d 0x24>;
				clock-names = "pdm_gate\0pdm_sysclk_srcpll\0pdm_dclk_srcpll\0pdm_dclk\0pdm_sysclk\0tdminlb_mpll\0tdminlb_mclk";
				mclk-fs = <0x100>;
				datain_src = <0x04>;
				datain_chnum = <0x04>;
				datain_chmask = <0x0f>;
				datain-lane-mask-in = <0x01 0x00 0x01 0x00>;
				datalb_src = <0x01>;
				datalb_chnum = <0x02>;
				datalb_chmask = <0x03>;
				datalb-lane-mask-in = <0x01 0x00 0x00 0x00>;
				status = "disabled";
				phandle = <0x10a>;
			};

			effect {
				compatible = "amlogic, snd-effect-v3";
				#sound-dai-cells = <0x00>;
				clocks = <0x1d 0x16 0x02 0x05 0x1d 0x34>;
				clock-names = "gate\0srcpll\0eqdrc";
				eqdrc_module = <0x01>;
				lane_mask = <0x01>;
				channel_mask = <0x03>;
				status = "okay";
				phandle = <0x10b>;
			};
		};

		bus@ff663000 {
			compatible = "simple-bus";
			reg = <0x00 0xff663000 0x00 0x1000>;
			#address-cells = <0x02>;
			#size-cells = <0x02>;
			ranges = <0x00 0x00 0x00 0xff663000 0x00 0x1000>;
			phandle = <0x10c>;

			earc@0 {
				compatible = "amlogic, sm1-snd-earc";
				#sound-dai-cells = <0x00>;
				status = "okay";
				reg = <0x00 0x800 0x00 0x400 0x00 0xc00 0x00 0x200 0x00 0xe00 0x00 0x200>;
				reg-names = "rx_cmdc\0rx_dmac\0rx_top";
				clocks = <0x1d 0x38 0x1d 0x39 0x02 0x04 0x02 0x04 0x1d 0x36 0x1d 0x37 0x02 0x04 0x02 0x0d>;
				clock-names = "rx_cmdc\0rx_dmac\0rx_cmdc_srcpll\0rx_dmac_srcpll";
				interrupts = <0x00 0x57 0x04>;
				interrupt-names = "earc_rx";
				phandle = <0xac>;
			};
		};

		aml_snd_iomap {
			compatible = "amlogic, snd-iomap";
			status = "okay";
			#address-cells = <0x02>;
			#size-cells = <0x02>;
			ranges;

			pdm_bus {
				reg = <0x00 0xff661000 0x00 0x400>;
			};

			audiobus_base {
				reg = <0x00 0xff660000 0x00 0x1000>;
			};

			audiolocker_base {
				reg = <0x00 0xff661400 0x00 0x400>;
			};

			eqdrc_base {
				reg = <0x00 0xff662000 0x00 0x1000>;
			};

			reset_base {
				reg = <0x00 0xffd01000 0x00 0x1000>;
			};

			vad_base {
				reg = <0x00 0xff661800 0x00 0x400>;
			};

			resampleA_base {
				reg = <0x00 0xff661c00 0x00 0x104>;
			};

			resampleB_base {
				reg = <0x00 0xff664000 0x00 0x104>;
			};
		};
	};

	rc@0xff808040 {
		compatible = "amlogic, aml_remote";
		dev_name = "meson-remote";
		reg = <0x00 0xff808040 0x00 0x44 0x00 0xff808000 0x00 0x20>;
		status = "okay";
		protocol = <0x01>;
		led_blink = <0x01>;
		led_blink_frq = <0x64>;
		interrupts = <0x00 0xc4 0x01>;
		pinctrl-names = "default";
		pinctrl-0 = <0x25>;
		map = <0x26>;
		max_frame_time = <0xc8>;
		phandle = <0x10d>;
	};

	custom_maps {
		mapnum = <0x06>;
		map0 = <0x27>;
		map1 = <0x28>;
		map2 = <0x29>;
		map3 = <0x2a>;
		map4 = <0x2b>;
		map5 = <0x2c>;
		phandle = <0x26>;

		map_0 {
			mapname = "amlogic-remote-1";
			customcode = <0xfe01>;
			release_delay = <0x39>;
			size = <0x28>;
			keymap = <0x1e000b 0x74 0x130002 0x120003 0x100004 0x170005 0x160006 0x140007 0x1b0008 0x1a0009 0x18000a 0x590067 0x51006c 0x540069 0x55001c 0x15006a 0x40192 0x60193 0x410071 0x5c0066 0x58007d 0x500079 0x4c0078 0xd007a 0x11007b 0x30089 0x50080 0xa004b 0x4d004c 0xe0090 0x44008f 0x7008e 0xc0091 0x1d0041 0x9008a 0x1c003e 0x1008d 0x480073 0xb0072 0x19009e>;
			phandle = <0x27>;
		};

		map_1 {
			mapname = "amlogic-remote-2";
			customcode = <0x4a69>;
			release_delay = <0x50>;
			size = <0x15>;
			keymap = <0x70000a 0x710009 0x720008 0x730007 0x740006 0x750005 0x760002 0x77000b 0x78001e 0x790030 0x7a002e 0x7b0020 0x7c0012 0x7d0040 0x7e0041 0x7f0042 0x800043 0x810044 0x820045 0x830003 0x840004>;
			phandle = <0x28>;
		};

		map_2 {
			mapname = "amlogic-remote-3";
			customcode = <0xbd02>;
			release_delay = <0x50>;
			size = <0x11>;
			keymap = <0xca0067 0xd2006c 0x990069 0xc1006a 0xce0061 0x450074 0xc50085 0x800071 0xd0000f 0xd6007d 0x950066 0xdd0068 0x8c006d 0x890083 0x9c0082 0x9a0078 0xcd0079>;
			phandle = <0x29>;
		};

		map_3 {
			mapname = "amlogic-remote-4";
			customcode = <0xff00>;
			release_delay = <0x50>;
			size = <0x1f>;
			keymap = <0x210074 0x230073 0x240072 0xa60166 0x25008b 0x330192 0x340193 0x150067 0x16006c 0x170069 0x18006a 0x19001c 0x48009e 0x470066 0x61016a 0x490043 0x4a0244 0x4600d9 0x6300fa 0x1a0044 0x10002 0x20003 0x30004 0x40005 0x50006 0x60007 0x70008 0x80009 0x9000a 0xa000b 0xed00ed>;
			phandle = <0x2a>;
		};

		map_4 {
			mapname = "amlogic-remote-5";
			customcode = <0x21d>;
			release_delay = <0x50>;
			size = <0x2a>;
			keymap = <0x74 0x480073 0xb0072 0x40068 0x6006d 0x590067 0x51006c 0x540069 0x15006a 0x55001c 0x19009e 0x5c0066 0x410071 0x30077 0x1f007a 0x2007b 0x4c0078 0x500079 0x10080 0x130002 0x120003 0x100004 0x170005 0x160006 0x140007 0x1b0008 0x1a0009 0x18000a 0x1e000b 0x580040 0x900b5 0x110041 0x800a6 0x1c00ab 0x450042 0x70043 0x490085 0x2000b3 0xa018e 0x4d00bd 0xe0190 0xc0191>;
			phandle = <0x2b>;
		};

		map_5 {
			mapname = "amlogic-remote-6";
			customcode = <0xf708>;
			release_delay = <0x50>;
			size = <0x1d>;
			keymap = <0xa0074 0x580073 0x5d0072 0x5a0192 0x5f0193 0x67 0x1006c 0x30069 0x2006a 0x1f001c 0x1c009e 0xc0066 0xd0071 0x30000e 0x660244 0x5004c 0x9004d 0x420040 0x740041 0x110002 0x120003 0x130004 0x140005 0x150006 0x160007 0x170008 0x180009 0x19000a 0x10000b>;
			phandle = <0x2c>;
		};
	};

	serial@ffd24000 {
		compatible = "amlogic, meson-uart";
		reg = <0x00 0xffd24000 0x00 0x18>;
		interrupts = <0x00 0x1a 0x01>;
		status = "okay";
		clocks = <0x14 0x02 0x2e>;
		clock-names = "clk_uart\0clk_gate";
		fifosize = <0x80>;
		pinctrl-names = "default";
		pinctrl-0 = <0x2d>;
		phandle = <0x10e>;
	};

	serial@ffd23000 {
		compatible = "amlogic, meson-uart";
		reg = <0x00 0xffd23000 0x00 0x18>;
		interrupts = <0x00 0x4b 0x01>;
		status = "disabled";
		clocks = <0x14 0x02 0x3c>;
		clock-names = "clk_uart\0clk_gate";
		fifosize = <0x40>;
		pinctrl-names = "default";
		pinctrl-0 = <0x2e>;
		phandle = <0x10f>;
	};

	serial@ffd22000 {
		compatible = "amlogic, meson-uart";
		reg = <0x00 0xffd22000 0x00 0x18>;
		interrupts = <0x00 0x5d 0x01>;
		status = "disabled";
		clocks = <0x14 0x02 0x3c>;
		clock-names = "clk_uart\0clk_gate";
		fifosize = <0x40>;
		pinctrl-names = "default";
		pinctrl-0 = <0x2f>;
		phandle = <0x110>;
	};

	pcieA@fc000000 {
		compatible = "amlogic, amlogic-pcie-v2\0snps,dw-pcie";
		reg = <0x00 0xfc000000 0x00 0x400000 0x00 0xff648000 0x00 0x2000 0x00 0xfc400000 0x00 0x200000 0x00 0xff646000 0x00 0x2000 0x00 0xffd01080 0x00 0x10>;
		reg-names = "elbi\0cfg\0config\0phy\0reset";
		interrupts = <0x00 0xdd 0x00>;
		#interrupt-cells = <0x01>;
		bus-range = <0x00 0xff>;
		#address-cells = <0x03>;
		#size-cells = <0x02>;
		interrupt-map-mask = <0x00 0x00 0x00 0x00>;
		interrupt-map = <0x00 0x00 0x00 0x00 0x01 0x00 0xdf 0x01>;
		device_type = "pci";
		ranges = <0x81000000 0x00 0x00 0x00 0xfc600000 0x00 0x100000 0x82000000 0x00 0xfc700000 0x00 0xfc700000 0x00 0x1900000>;
		num-lanes = <0x01>;
		pcie-num = <0x01>;
		clocks = <0x02 0x18 0x02 0x3f 0x02 0x42>;
		clock-names = "pcie_refpll\0pcie\0pcie_phy";
		gpio-type = <0x02>;
		pcie-apb-rst-bit = <0x0f>;
		pcie-phy-rst-bit = <0x0e>;
		pcie-ctrl-a-rst-bit = <0x0c>;
		pwr-ctl = <0x01>;
		pcie-ctrl-sleep-shift = <0x12>;
		pcie-hhi-mem-pd-shift = <0x1a>;
		pcie-hhi-mem-pd-mask = <0x0f>;
		pcie-ctrl-iso-shift = <0x12>;
		status = "disable";
		reset-gpio = <0x18 0x49 0x00>;
		phandle = <0x111>;
	};

	amhdmitx {
		compatible = "amlogic, amhdmitx";
		dev_name = "amhdmitx";
		status = "okay";
		vend-data = <0x30>;
		pinctrl-names = "default\0hdmitx_i2c";
		pinctrl-0 = <0x31 0x32>;
		pinctrl-1 = <0x33 0x34>;
		clocks = <0x02 0x55 0x02 0x4e 0x02 0x4f 0x02 0x95 0x02 0x8c>;
		clock-names = "venci_top_gate\0venci_0_gate\0venci_1_gate\0hdmi_vapb_clk\0hdmi_vpu_clk";
		interrupts = <0x00 0x39 0x01>;
		interrupt-names = "hdmitx_hpd";
		ic_type = <0x0c>;
		phandle = <0x112>;

		vend_data {
			vendor_name = "Amlogic";
			product_desc = "MBox Meson Ref";
			vendor_id = <0x00>;
			phandle = <0x30>;
		};
	};

	galcore {
		compatible = "amlogic, galcore";
		dev_name = "galcore";
		status = "okay";
		clocks = <0x02 0xe8 0x02 0xe7>;
		clock-names = "cts_vipnanoq_axi_clk_composite\0cts_vipnanoq_core_clk_composite";
		interrupts = <0x00 0xba 0x04>;
		interrupt-names = "galcore";
		reg = <0x00 0xff100000 0x00 0x800 0x00 0xff000000 0x00 0x400000 0x00 0xff63c118 0x00 0x00 0x00 0xff63c11c 0x00 0x00 0x00 0xffd01088 0x00 0x00 0x00 0xff63c1c8 0x00 0x00>;
		reg-names = "NN_REG\0NN_SRAM\0NN_MEM0\0NN_MEM1\0NN_RESET\0NN_CLK";
		nn_power_version = <0x03>;
		nn_efuse = <0xff63003c 0x20>;
	};

	aocec {
		compatible = "amlogic, aocec-sm1";
		device_name = "aocec";
		status = "okay";
		vendor_name = "Amlogic";
		vendor_id = <0x00>;
		product_desc = "SM1";
		cec_osd_string = "AML_MBOX";
		cec_version = <0x05>;
		port_num = <0x01>;
		output = <0x01>;
		ee_cec;
		arc_port_mask = <0x02>;
		interrupts = <0x00 0xcb 0x01 0x00 0xc7 0x01>;
		interrupt-names = "hdmi_aocecb\0hdmi_aocec";
		pinctrl-names = "default\0hdmitx_aocecb\0cec_pin_sleep";
		pinctrl-0 = <0x35>;
		pinctrl-1 = <0x36>;
		pinctrl-2 = <0x36>;
		reg = <0x00 0xff80023c 0x00 0x04 0x00 0xff800000 0x00 0x400 0x00 0xff634400 0x00 0x70>;
		reg-names = "ao_exit\0ao\0periphs";
		phandle = <0x113>;
	};

	vdin0 {
		compatible = "amlogic, vdin";
		dev_name = "vdin0";
		status = "disable";
		reserve-iomap = "true";
		flag_cma = <0x00>;
		interrupts = <0x00 0x53 0x01>;
		rdma-irq = <0x02>;
		vdin_id = <0x00>;
		cma_size = <0x14>;
		tv_bit_mode = <0x01>;
		phandle = <0x114>;
	};

	vdin1 {
		compatible = "amlogic, vdin";
		dev_name = "vdin1";
		status = "okay";
		reserve-iomap = "true";
		flag_cma = <0x00>;
		interrupts = <0x00 0x55 0x01>;
		rdma-irq = <0x04>;
		vdin_id = <0x01>;
		memory-region = <0x37>;
		tv_bit_mode = <0x01>;
		phandle = <0x115>;
	};

	vout {
		compatible = "amlogic, vout";
		dev_name = "vout";
		status = "okay";
		fr_policy = <0x00>;
	};

	vout2 {
		compatible = "amlogic, vout2";
		dev_name = "vout";
		status = "okay";
		clocks = <0x02 0xc4 0x02 0xc9>;
		clock-names = "vpu_clkc0\0vpu_clkc";
		fr_policy = <0x00>;
	};

	dummy_venc {
		compatible = "amlogic, dummy_venc";
		status = "okay";
		clocks = <0x02 0x56 0x02 0x50 0x02 0x51 0x02 0x55 0x02 0x4e 0x02 0x4f 0x02 0x5d 0x02 0x5f>;
		clock-names = "encp_top_gate\0encp_int_gate0\0encp_int_gate1\0venci_top_gate\0enci_int_gate0\0enci_int_gate1\0encl_top_gate\0encl_int_gate";
		phandle = <0x116>;
	};

	vdac {
		compatible = "amlogic, vdac-sm1";
		status = "okay";
	};

	canvas {
		compatible = "amlogic, meson, canvas";
		dev_name = "amlogic-canvas";
		status = "okay";
		reg = <0x00 0xff638000 0x00 0x2000>;
		phandle = <0x117>;
	};

	ge2d {
		compatible = "amlogic, ge2d-sm1";
		dev_name = "ge2d";
		status = "okay";
		interrupts = <0x00 0x92 0x01>;
		interrupt-names = "ge2d";
		clocks = <0x02 0x95 0x02 0x3d 0x02 0x96>;
		clock-names = "clk_vapb_0\0clk_ge2d\0clk_ge2d_gate";
		reg = <0x00 0xff940000 0x00 0x10000>;
	};

	meson-amvideom {
		compatible = "amlogic, amvideom";
		dev_name = "amvideom";
		status = "okay";
		interrupts = <0x00 0x03 0x01>;
		interrupt-names = "vsync";
	};

	codec_io {
		compatible = "amlogic, codec_io";
		status = "okay";
		#address-cells = <0x02>;
		#size-cells = <0x02>;
		ranges;
		phandle = <0x118>;

		io_cbus_base {
			reg = <0x00 0xffd00000 0x00 0x100000>;
		};

		io_dos_base {
			reg = <0x00 0xff620000 0x00 0x10000>;
		};

		io_hiubus_base {
			reg = <0x00 0xff63c000 0x00 0x2000>;
		};

		io_aobus_base {
			reg = <0x00 0xff800000 0x00 0x10000>;
		};

		io_vcbus_base {
			reg = <0x00 0xff900000 0x00 0x40000>;
		};

		io_dmc_base {
			reg = <0x00 0xff638000 0x00 0x2000>;
		};

		io_efuse_base {
			reg = <0x00 0xff630000 0x00 0x2000>;
		};
	};

	mesonstream {
		compatible = "amlogic, codec, streambuf";
		dev_name = "mesonstream";
		status = "okay";
		clocks = <0x02 0x40 0x02 0x39 0x02 0x43 0x02 0x22 0x02 0x0b 0x02 0xa5 0x02 0xae 0x02 0xb7 0x02 0xc0>;
		clock-names = "parser_top\0demux\0ahbarb0\0vdec\0clk_81\0clk_vdec_mux\0clk_hcodec_mux\0clk_hevc_mux\0clk_hevcb_mux";
	};

	vdec {
		compatible = "amlogic, vdec";
		dev_name = "vdec.0";
		status = "okay";
		interrupts = <0x00 0x03 0x01 0x00 0x17 0x01 0x00 0x20 0x01 0x00 0x2b 0x01 0x00 0x2c 0x01 0x00 0x2d 0x01 0x00 0x48 0x01>;
		interrupt-names = "vsync\0demux\0parser\0mailbox_0\0mailbox_1\0mailbox_2\0parser_b";
	};

	vcodec_dec {
		compatible = "amlogic, vcodec-dec";
		dev_name = "aml-vcodec-dec";
		status = "okay";
	};

	video_composer {
		compatible = "amlogic, video_composer";
		dev_name = "video_composer";
		status = "okay";
	};

	amvenc_avc {
		compatible = "amlogic, amvenc_avc";
		dev_name = "amvenc_avc";
		status = "okay";
		interrupts = <0x00 0x2d 0x01>;
		interrupt-names = "mailbox_2";
	};

	hevc_enc {
		compatible = "cnm, HevcEnc";
		dev_name = "HevcEnc";
		status = "okay";
		interrupts = <0x00 0xbb 0x01>;
		interrupt-names = "wave420l_irq";
		#address-cells = <0x02>;
		#size-cells = <0x02>;
		ranges;

		io_reg_base {
			reg = <0x00 0xff610000 0x00 0x4000>;
		};
	};

	rdma {
		compatible = "amlogic, meson, rdma";
		dev_name = "amlogic-rdma";
		status = "okay";
		interrupts = <0x00 0x59 0x01>;
		interrupt-names = "rdma";
	};

	fb {
		compatible = "amlogic, meson-sm1";
		memory-region = <0x38>;
		dev_name = "meson-fb";
		status = "okay";
		interrupts = <0x00 0x03 0x01 0x00 0x38 0x01 0x00 0x59 0x01>;
		interrupt-names = "viu-vsync\0viu2-vsync\0rdma";
		display_mode_default = "1080p60hz";
		scale_mode = <0x01>;
		display_size_default = <0x780 0x438 0x780 0x870 0x20>;
		clocks = <0x02 0xc9>;
		clock-names = "vpu_clkc";
		mem_size = <0x800000 0x1980000 0x100000 0x100000 0x800000>;
		logo_addr = "0x7f800000";
		mem_alloc = <0x00>;
		pxp_mode = <0x00>;
		phandle = <0x119>;
	};

	emmc@ffe07000 {
		status = "okay";
		compatible = "amlogic, meson-mmc-sm1";
		reg = <0x00 0xffe07000 0x00 0x800>;
		interrupts = <0x00 0xbf 0x01>;
		pinctrl-names = "emmc_clk_cmd_pins\0emmc_all_pins";
		pinctrl-0 = <0x39>;
		pinctrl-1 = <0x3a 0x3b>;
		clocks = <0x02 0x35 0x02 0x72 0x02 0x02 0x02 0x20 0x14>;
		clock-names = "core\0clkin0\0clkin1\0clkin2\0xtal";
		bus-width = <0x08>;
		cap-sd-highspeed;
		cap-mmc-highspeed;
		max-frequency = <0xbebc200>;
		non-removable;
		disable-wp;
		phandle = <0x11a>;

		emmc {
			pinname = "emmc";
			ocr_avail = <0x200080>;
			tx_delay = <0x13>;
			co_phase = <0x03>;
			max_req_size = <0x20000>;
			gpio_dat3 = <0x18 0x1d 0x00>;
			hw_reset = <0x18 0x26 0x00>;
			card_type = <0x01>;
			caps = "MMC_CAP_8_BIT_DATA\0MMC_CAP_MMC_HIGHSPEED\0MMC_CAP_SD_HIGHSPEED\0MMC_CAP_NONREMOVABLE\0MMC_CAP_HW_RESET\0MMC_CAP_ERASE\0MMC_CAP_CMD23\0MMC_CAP_DRIVER_TYPE_D";
			caps2 = "MMC_CAP2_HS200\0MMC_CAP2_HS400";
			f_min = <0x61a80>;
			f_max = <0xbebc200>;
		};
	};

	sd@ffe05000 {
		status = "okay";
		compatible = "amlogic, meson-mmc-sm1";
		reg = <0x00 0xffe05000 0x00 0x800>;
		interrupts = <0x00 0xbe 0x01>;
		pinctrl-names = "sd_all_pins\0sd_clk_cmd_pins\0sd_1bit_pins\0sd_clk_cmd_uart_pins\0sd_1bit_uart_pins\0sd_to_ao_uart_pins\0ao_to_sd_uart_pins\0sd_to_ao_jtag_pins\0ao_to_sd_jtag_pins\0sd_all_pd_pins";
		pinctrl-0 = <0x3c>;
		pinctrl-1 = <0x3d>;
		pinctrl-2 = <0x3e>;
		pinctrl-3 = <0x3f 0x3d 0x40>;
		pinctrl-4 = <0x3f 0x3e 0x40>;
		pinctrl-5 = <0x3c 0x41>;
		pinctrl-6 = <0x3f 0x40>;
		pinctrl-7 = <0x3c 0x41>;
		pinctrl-8 = <0x3f 0x40>;
		pinctrl-9 = <0x42>;
		clocks = <0x02 0x34 0x02 0x6e 0x02 0x02 0x02 0x05 0x14>;
		clock-names = "core\0clkin0\0clkin1\0clkin2\0xtal";
		bus-width = <0x04>;
		cap-sd-highspeed;
		cap-mmc-highspeed;
		max-frequency = <0x5f5e100>;
		disable-wp;
		phandle = <0x11b>;

		sd {
			pinname = "sd";
			ocr_avail = <0x200080>;
			max_req_size = <0x20000>;
			gpio_dat3 = <0x18 0x2d 0x00>;
			jtag_pin = <0x18 0x2a 0x00>;
			gpio_cd = <0x18 0x30 0x00>;
			card_type = <0x05>;
			caps = "MMC_CAP_4_BIT_DATA\0MMC_CAP_MMC_HIGHSPEED\0MMC_CAP_SD_HIGHSPEED";
			f_min = <0x61a80>;
			f_max = <0x2faf080>;
		};
	};

	sdio@ffe03000 {
		status = "okay";
		compatible = "amlogic, meson-mmc-sm1";
		reg = <0x00 0xffe03000 0x00 0x800>;
		interrupts = <0x00 0xbd 0x04>;
		pinctrl-names = "sdio_all_pins\0sdio_clk_cmd_pins";
		pinctrl-0 = <0x43>;
		pinctrl-1 = <0x44>;
		clocks = <0x02 0x33 0x02 0x6a 0x02 0x02 0x02 0x05 0x14>;
		clock-names = "core\0clkin0\0clkin1\0clkin2\0xtal";
		bus-width = <0x04>;
		cap-sd-highspeed;
		cap-mmc-highspeed;
		max-frequency = <0x5f5e100>;
		disable-wp;
		phandle = <0x11c>;

		sdio {
			pinname = "sdio";
			ocr_avail = <0x200080>;
			max_req_size = <0x20000>;
			card_type = <0x03>;
			caps = "MMC_CAP_4_BIT_DATA\0MMC_CAP_MMC_HIGHSPEED\0MMC_CAP_SD_HIGHSPEED\0MMC_CAP_NONREMOVABLE\0MMC_CAP_UHS_SDR12\0MMC_CAP_UHS_SDR25\0MMC_CAP_UHS_SDR50\0MMC_CAP_UHS_SDR104\0MMC_PM_KEEP_POWER\0MMC_CAP_SDIO_IRQ";
			f_min = <0x61a80>;
			f_max = <0xbebc200>;
		};
	};

	nfc@0 {
		compatible = "amlogic, aml_mtd_nand";
		dev_name = "mtdnand";
		status = "disabled";
		reg = <0x00 0xffe07800 0x00 0x200>;
		interrupts = <0x00 0x22 0x01>;
		pinctrl-names = "nand_rb_mod\0nand_norb_mod\0nand_cs_only";
		pinctrl-0 = <0x45>;
		pinctrl-1 = <0x45>;
		pinctrl-2 = <0x46>;
		device_id = <0x00>;
		clocks = <0x02 0x35 0x02 0x02>;
		clock-names = "gate\0fdiv2pll";
		bl_mode = <0x01>;
		fip_copies = <0x04>;
		fip_size = <0x200000>;
		nand_clk_ctrl = <0xffe07000>;
		plat-names = "bootloader\0nandnormal";
		plat-num = <0x02>;
		plat-part-0 = <0x47>;
		plat-part-1 = <0x48>;
		phandle = <0x11d>;

		bootloader {
			enable_pad = "ce0";
			busy_pad = "rb0";
			timming_mode = "mode5";
			bch_mode = "bch8_1k";
			t_rea = <0x14>;
			t_rhoh = <0x0f>;
			chip_num = <0x01>;
			part_num = <0x00>;
			rb_detect = <0x01>;
			phandle = <0x47>;
		};

		nandnormal {
			enable_pad = "ce0";
			busy_pad = "rb0";
			timming_mode = "mode5";
			bch_mode = "bch8_1k";
			plane_mode = "twoplane";
			t_rea = <0x14>;
			t_rhoh = <0x0f>;
			chip_num = <0x02>;
			part_num = <0x03>;
			partition = <0x49>;
			rb_detect = <0x01>;
			phandle = <0x48>;
		};

		nand_partition {
			phandle = <0x49>;

			tpl {
				offset = <0x00 0x00>;
				size = <0x00 0x00>;
			};

			logo {
				offset = <0x00 0x00>;
				size = <0x00 0x200000>;
			};

			recovery {
				offset = <0x00 0x00>;
				size = <0x00 0x1000000>;
			};

			boot {
				offset = <0x00 0x00>;
				size = <0x00 0x1000000>;
			};

			system {
				offset = <0x00 0x00>;
				size = <0x00 0x4000000>;
			};

			data {
				offset = <0xffffffff 0xffffffff>;
				size = <0x00 0x00>;
			};
		};
	};

	pwmao_d-regulator {
		compatible = "pwm-regulator";
		pwms = <0x4a 0x01 0x4e2 0x00>;
		regulator-name = "vddcpu0";
		regulator-min-microvolt = <0xafc80>;
		regulator-max-microvolt = <0xf9060>;
		regulator-always-on;
		max-duty-cycle = <0x4e2>;
		voltage-table = <0xf9060 0x00 0xf6950 0x03 0xf4240 0x06 0xf1b30 0x0a 0xef420 0x0d 0xecd10 0x10 0xea600 0x14 0xe7ef0 0x17 0xe57e0 0x1a 0xe30d0 0x1e 0xe09c0 0x21 0xde2b0 0x24 0xdbba0 0x28 0xd9490 0x2b 0xd6d80 0x2e 0xd4670 0x32 0xd1f60 0x35 0xcf850 0x38 0xcd140 0x3c 0xcaa30 0x3f 0xc8320 0x43 0xc5c10 0x46 0xc3500 0x49 0xc0df0 0x4c 0xbe6e0 0x50 0xbbfd0 0x53 0xb98c0 0x56 0xb71b0 0x5a 0xb4aa0 0x5d 0xb2390 0x60 0xafc80 0x64>;
		status = "okay";
		phandle = <0x0e>;
	};

	ddr_bandwidth {
		compatible = "amlogic, ddr-bandwidth";
		status = "okay";
		reg = <0x00 0xff638000 0x00 0x100 0x00 0xff638c00 0x00 0x100>;
		sec_base = <0xff639000>;
		interrupts = <0x00 0x34 0x01>;
		interrupt-names = "ddr_bandwidth";
	};

	dmc_monitor {
		compatible = "amlogic, dmc_monitor";
		status = "okay";
		reg_base = <0xff639000>;
		interrupts = <0x00 0x33 0x01>;
	};

	defendkey {
		compatible = "amlogic, defendkey";
		reg = <0x00 0xff630218 0x00 0x04>;
		mem_size = <0x00 0x100000>;
		status = "okay";
		phandle = <0x11e>;
	};

	aml_dma {
		compatible = "amlogic,aml_txlx_dma";
		reg = <0x00 0xff63e000 0x00 0x48>;
		interrupts = <0x00 0xb4 0x01>;

		aml_aes {
			compatible = "amlogic,aes_g12a_dma";
			dev_name = "aml_aes_dma";
			status = "okay";
		};

		aml_sha {
			compatible = "amlogic,sha_dma";
			dev_name = "aml_sha_dma";
			status = "okay";
		};
	};

	rng {
		compatible = "amlogic,meson-rng";
		status = "okay";
		#address-cells = <0x02>;
		#size-cells = <0x02>;
		reg = <0x00 0xff630218 0x00 0x04>;
		quality = [03 e8];
	};

	efuse {
		compatible = "amlogic, efuse";
		read_cmd = <0x82000030>;
		write_cmd = <0x82000031>;
		get_max_cmd = <0x82000033>;
		key = <0x4b>;
		clocks = <0x02 0x61>;
		clock-names = "efuse_clk";
		status = "disabled";
		phandle = <0x11f>;
	};

	cpu_ver_name {
		compatible = "amlogic, cpu-major-id-sm1";
	};

	p_tsensor@ff634800 {
		compatible = "amlogic, r1p1-tsensor";
		device_name = "meson-pthermal";
		status = "okay";
		reg = <0x00 0xff634800 0x00 0x50 0x00 0xff800268 0x00 0x04>;
		cal_type = <0x01>;
		cal_a = <0x144>;
		cal_b = <0x1a8>;
		cal_c = <0xc57>;
		cal_d = <0x24c3>;
		rtemp = <0x1c138>;
		interrupts = <0x00 0x23 0x00>;
		clocks = <0x02 0xd6>;
		clock-names = "ts_comp";
		#thermal-sensor-cells = <0x01>;
		phandle = <0x4c>;
	};

	d_tsensor@ff634c00 {
		compatible = "amlogic, r1p1-tsensor";
		device_name = "meson-dthermal";
		status = "okay";
		reg = <0x00 0xff634c00 0x00 0x50 0x00 0xff800230 0x00 0x04>;
		cal_type = <0x01>;
		cal_a = <0x144>;
		cal_b = <0x1a8>;
		cal_c = <0xc57>;
		cal_d = <0x24c3>;
		rtemp = <0x1c138>;
		interrupts = <0x00 0x24 0x00>;
		clocks = <0x02 0xd6>;
		clock-names = "ts_comp";
		#thermal-sensor-cells = <0x01>;
		phandle = <0x52>;
	};

	meson-cooldev@0 {
		status = "okay";
		compatible = "amlogic, meson-cooldev";
		device_name = "mcooldev";
		phandle = <0x120>;

		cooling_devices {

			cpufreq_cool_cluster0 {
				min_state = <0xf4240>;
				dyn_coeff = <0x7d>;
				gpu_pp = <0x02>;
				cluster_id = <0x00>;
				node_name = "cpufreq_cool0";
				device_type = "cpufreq";
			};

			cpucore_cool_cluster0 {
				min_state = <0x01>;
				dyn_coeff = <0x00>;
				gpu_pp = <0x02>;
				cluster_id = <0x00>;
				node_name = "cpucore_cool0";
				device_type = "cpucore";
			};

			gpufreq_cool {
				min_state = <0x1f4>;
				dyn_coeff = <0xd7>;
				gpu_pp = <0x02>;
				cluster_id = <0x00>;
				node_name = "gpufreq_cool0";
				device_type = "gpufreq";
			};

			gpucore_cool {
				min_state = <0x01>;
				dyn_coeff = <0x00>;
				gpu_pp = <0x02>;
				cluster_id = <0x00>;
				node_name = "gpucore_cool0";
				device_type = "gpucore";
			};
		};

		cpufreq_cool0 {
			#cooling-cells = <0x02>;
			phandle = <0x4e>;
		};

		cpucore_cool0 {
			#cooling-cells = <0x02>;
			phandle = <0x4f>;
		};

		gpufreq_cool0 {
			#cooling-cells = <0x02>;
			phandle = <0x50>;
		};

		gpucore_cool0 {
			#cooling-cells = <0x02>;
			phandle = <0x51>;
		};
	};

	thermal-zones {

		soc_thermal {
			polling-delay = <0x3e8>;
			polling-delay-passive = <0x64>;
			sustainable-power = <0x582>;
			thermal-sensors = <0x4c 0x00>;
			phandle = <0x121>;

			trips {

				trip-point@0 {
					temperature = <0xea60>;
					hysteresis = <0x1388>;
					type = "passive";
					phandle = <0x122>;
				};

				trip-point@1 {
					temperature = <0x14c08>;
					hysteresis = <0x1388>;
					type = "passive";
					phandle = <0x4d>;
				};

				trip-point@2 {
					temperature = <0x17318>;
					hysteresis = <0x1388>;
					type = "hot";
					phandle = <0x123>;
				};

				trip-point@3 {
					temperature = <0x1adb0>;
					hysteresis = <0x3e8>;
					type = "critical";
					phandle = <0x124>;
				};
			};

			cooling-maps {

				cpufreq_cooling_map {
					trip = <0x4d>;
					cooling-device = <0x4e 0x00 0x04>;
					contribution = <0x400>;
				};

				cpucore_cooling_map {
					trip = <0x4d>;
					cooling-device = <0x4f 0x00 0x03>;
					contribution = <0x400>;
				};

				gpufreq_cooling_map {
					trip = <0x4d>;
					cooling-device = <0x50 0x00 0x03>;
					contribution = <0x400>;
				};

				gpucore_cooling_map {
					trip = <0x4d>;
					cooling-device = <0x51 0x00 0x02>;
					contribution = <0x400>;
				};
			};
		};

		ddr_thermal {
			polling-delay = <0x7d0>;
			polling-delay-passive = <0x3e8>;
			sustainable-power = <0x582>;
			thermal-sensors = <0x52 0x01>;
			phandle = <0x125>;

			trips {

				trip-point@0 {
					temperature = <0xea60>;
					hysteresis = <0x1388>;
					type = "passive";
					phandle = <0x126>;
				};

				trip-point@1 {
					temperature = <0x14c08>;
					hysteresis = <0x1388>;
					type = "passive";
					phandle = <0x127>;
				};

				trip-point@2 {
					temperature = <0x17318>;
					hysteresis = <0x1388>;
					type = "hot";
					phandle = <0x128>;
				};

				trip-point@3 {
					temperature = <0x1adb0>;
					hysteresis = <0x3e8>;
					type = "critical";
					phandle = <0x129>;
				};
			};
		};
	};

	firmware {

		android {
			compatible = "android,firmware";

			vbmeta {
				compatible = "android,vbmeta";
				parts = "vbmeta,boot,system,vendor,oem";
				by_name_prefix = "/dev/block";
			};
		};
	};

	partitions {
		parts = <0x10>;
		part-0 = <0x53>;
		part-1 = <0x54>;
		part-2 = <0x55>;
		part-3 = <0x56>;
		part-4 = <0x57>;
		part-5 = <0x58>;
		part-6 = <0x59>;
		part-7 = <0x5a>;
		part-8 = <0x5b>;
		part-9 = <0x5c>;
		part-10 = <0x5d>;
		part-11 = <0x5e>;
		part-12 = <0x5f>;
		part-13 = <0x60>;
		part-14 = <0x61>;
		part-15 = <0x62>;
		phandle = <0x12a>;

		logo {
			pname = "logo";
			size = <0x00 0x800000>;
			mask = <0x01>;
			phandle = <0x53>;
		};

		recovery {
			pname = "recovery";
			size = <0x00 0x1800000>;
			mask = <0x01>;
			phandle = <0x54>;
		};

		tee {
			pname = "tee";
			size = <0x00 0x2000000>;
			mask = <0x01>;
			phandle = <0x55>;
		};

		factory {
			pname = "factory";
			size = <0x00 0x800000>;
			mask = <0x11>;
			phandle = <0x56>;
		};

		misc {
			pname = "misc";
			size = <0x00 0x200000>;
			mask = <0x01>;
			phandle = <0x57>;
		};

		dtbo {
			pname = "dtbo";
			size = <0x00 0x200000>;
			mask = <0x01>;
			phandle = <0x58>;
		};

		cri_data {
			pname = "cri_data";
			size = <0x00 0x800000>;
			mask = <0x02>;
			phandle = <0x59>;
		};

		rsv {
			pname = "rsv";
			size = <0x00 0x1000000>;
			mask = <0x01>;
			phandle = <0x5c>;
		};

		metadata {
			pname = "metadata";
			size = <0x00 0x1000000>;
			mask = <0x01>;
			phandle = <0x5d>;
		};

		vbmeta {
			pname = "vbmeta";
			size = <0x00 0x200000>;
			mask = <0x01>;
			phandle = <0x5e>;
		};

		oem {
			pname = "oem";
			size = <0x00 0x3200000>;
			mask = <0x01>;
			phandle = <0x5f>;
		};

		param {
			pname = "param";
			size = <0x00 0x1000000>;
			mask = <0x02>;
			phandle = <0x5a>;
		};

		boot {
			pname = "boot";
			size = <0x00 0x1000000>;
			mask = <0x01>;
			phandle = <0x5b>;
		};

		super {
			pname = "super";
			size = <0x00 0x78000000>;
			mask = <0x01>;
			phandle = <0x60>;
		};

		cache {
			pname = "cache";
			size = <0x00 0x2bc00000>;
			mask = <0x02>;
			phandle = <0x61>;
		};

		data {
			pname = "data";
			size = <0xffffffff 0xffffffff>;
			mask = <0x04>;
			phandle = <0x62>;
		};
	};

	lcd {
		compatible = "amlogic, lcd-sm1";
		mode = "tablet";
		status = "okay";
		key_valid = <0x00>;
		clocks = <0x02 0x24 0x02 0x31 0x02 0x9a 0x02 0x5d 0x02 0x5f 0x02 0x07>;
		clock-names = "dsi_host_gate\0dsi_phy_gate\0dsi_meas\0encl_top_gate\0encl_int_gate\0gp0_pll";
		reg = <0x00 0xffd07000 0x00 0x400 0x00 0xff644000 0x00 0x200>;
		interrupts = <0x00 0x03 0x01 0x00 0x38 0x01>;
		interrupt-names = "vsync\0vsync2";
		pinctrl_version = <0x02>;
		lcd_cpu-gpios = <0x18 0x15 0x00 0x18 0x18 0x00>;
		lcd_cpu_gpio_names = "GPIOH_4\0GPIOH_7";
		phandle = <0x12b>;

		lcd_0 {
			model_name = "B080XAN01";
			interface = "mipi";
			basic_setting = <0x300 0x400 0x3b4 0x474 0x08 0x77 0x9f>;
			lcd_timing = <0x40 0x38 0x00 0x32 0x1e 0x00>;
			clk_attr = <0x00 0x00 0x01 0x3dd6dc0>;
			mipi_attr = <0x04 0x226 0x00 0x01 0x00 0x02 0x01 0x00>;
			dsi_init_on = <0x05 0x01 0x11 0xfd 0x01 0x14 0x05 0x01 0x29 0xfd 0x01 0x14 0xff 0x00>;
			dsi_init_off = <0x05 0x01 0x28 0xfd 0x01 0x0a 0x05 0x01 0x10 0xfd 0x01 0x0a 0xff 0x00>;
			extern_init = <0xff>;
			power_on_step = <0x00 0x01 0x00 0x64 0x00 0x00 0x00 0x0a 0x00 0x00 0x01 0x14 0x02 0x00 0x00 0x00 0xff 0x00 0x00 0x00>;
			power_off_step = <0x02 0x00 0x00 0x32 0x00 0x00 0x00 0x0a 0x00 0x01 0x01 0x64 0xff 0x00 0x00 0x00>;
			backlight_index = <0x00>;
		};

		lcd_1 {
			model_name = "P070ACB_FT";
			interface = "mipi";
			basic_setting = <0x258 0x400 0x302 0x42e 0x08 0x03 0x05>;
			lcd_timing = <0x0a 0x50 0x00 0x06 0x14 0x00>;
			clk_attr = <0x00 0x00 0x01 0x2f24d90>;
			mipi_attr = <0x04 0x190 0x00 0x01 0x00 0x02 0x00 0x00>;
			dsi_init_on = <0xff 0x0a 0xf0 0x03 0x00 0x01 0x1e 0xf0 0x03 0x00 0x00 0x0a 0xf0 0x03 0x00 0x01 0x1e 0xfc 0x02 0x04 0x03 0xff 0x00>;
			dsi_init_off = <0xff 0x00>;
			extern_init = <0x05>;
			power_on_step = <0x00 0x01 0x00 0xc8 0x02 0x00 0x00 0x00 0xff 0x00 0x00 0x00>;
			power_off_step = <0x02 0x00 0x00 0x00 0x00 0x00 0x00 0x14 0x00 0x01 0x01 0x64 0xff 0x00 0x00 0x00>;
			backlight_index = <0x00>;
		};

		lcd_7 {
			model_name = "EK79007";
			interface = "mipi";
			basic_setting = <0x400 0x258 0x54a 0x27c 0x08 0x77 0x50>;
			lcd_timing = <0x0a 0xa0 0x00 0x01 0x17 0x00>;
			clk_attr = <0x00 0x00 0x01 0x31466a0>;
			mipi_attr = <0x04 0x3e8 0x00 0x01 0x00 0x02 0x01 0x00>;
			dsi_init_on = <0xff 0xff>;
			dsi_init_off = <0xff 0xff>;
			extern_init = <0x06>;
			power_on_step = <0x00 0x00 0x01 0x0a 0x00 0x01 0x00 0x64 0x00 0x00 0x00 0xc8 0x00 0x01 0x01 0x64 0x02 0x00 0x00 0x64 0xff 0x00 0x00 0x00>;
			power_off_step = <0x02 0x00 0x00 0x00 0x00 0x01 0x00 0x64 0x00 0x00 0x01 0x64 0xff 0x00 0x00 0x00>;
			backlight_index = <0x00>;
		};

		lcd_8 {
			model_name = "SLT_720P";
			interface = "mipi";
			basic_setting = <0x500 0x2d0 0x636 0x2ee 0x08 0x10 0x09>;
			lcd_timing = <0x28 0x3c 0x00 0x05 0x14 0x00>;
			clk_attr = <0x00 0x00 0x01 0x46cf710>;
			mipi_attr = <0x04 0x226 0x00 0x01 0x00 0x00 0x01 0x00>;
			dsi_init_on = <0x05 0x01 0x11 0xff 0xc8 0x05 0x01 0x29 0xff 0x14 0xff 0xff>;
			dsi_init_off = <0x05 0x01 0x28 0xff 0x0a 0x05 0x01 0x10 0xff 0x0a 0xff 0xff>;
			extern_init = <0xff>;
			power_on_step = <0x03 0x07 0x00 0x64 0x02 0x00 0x00 0x00 0xff 0x00 0x00 0x00>;
			power_off_step = <0x02 0x00 0x00 0x00 0xff 0x00 0x00 0x00>;
			backlight_index = <0xff>;
		};
	};

	lcd_extern {
		compatible = "amlogic, lcd_extern";
		status = "okay";
		i2c_bus = "i2c_bus_0";
		key_valid = <0x00>;

		extern_0 {
			index = <0x00>;
			extern_name = "mipi_default";
			status = "okay";
			type = <0x02>;
			cmd_size = <0xff>;
			init_on = <0xfd 0x01 0x0a 0x05 0x01 0x11 0xfd 0x01 0x78 0x05 0x01 0x29 0xff 0x00>;
			init_off = <0x05 0x01 0x28 0xfd 0x01 0x0a 0x05 0x01 0x10 0xfd 0x01 0x96 0xff 0x00>;
		};

		extern_1 {
			index = <0x01>;
			extern_name = "mipi_default";
			status = "okay";
			type = <0x02>;
			cmd_size = <0xff>;
			init_on = <0x23 0x02 0xe0 0x00 0x23 0x02 0xe1 0x93 0x23 0x02 0xe2 0x65 0x23 0x02 0xe3 0xf8 0x23 0x02 0x80 0x03 0x23 0x02 0xe0 0x01 0x23 0x02 0x0c 0x74 0x23 0x02 0x17 0x00 0x23 0x02 0x18 0xef 0x23 0x02 0x19 0x00 0x23 0x02 0x1a 0x00 0x23 0x02 0x1b 0xef 0x23 0x02 0x1c 0x00 0x23 0x02 0x1f 0x70 0x23 0x02 0x20 0x2d 0x23 0x02 0x21 0x2d 0x23 0x02 0x22 0x7e 0x23 0x02 0x26 0xf3 0x23 0x02 0x37 0x09 0x23 0x02 0x38 0x04 0x23 0x02 0x39 0x00 0x23 0x02 0x3a 0x01 0x23 0x02 0x3c 0x90 0x23 0x02 0x3d 0xff 0x23 0x02 0x3e 0xff 0x23 0x02 0x3f 0xff 0x23 0x02 0x40 0x02 0x23 0x02 0x41 0x80 0x23 0x02 0x42 0x99 0x23 0x02 0x43 0x14 0x23 0x02 0x44 0x19 0x23 0x02 0x45 0x5a 0x23 0x02 0x4b 0x04 0x23 0x02 0x55 0x02 0x23 0x02 0x56 0x01 0x23 0x02 0x57 0x69 0x23 0x02 0x58 0x0a 0x23 0x02 0x59 0x0a 0x23 0x02 0x5a 0x2e 0x23 0x02 0x5b 0x19 0x23 0x02 0x5c 0x15 0x23 0x02 0x5d 0x77 0x23 0x02 0x5e 0x56 0x23 0x02 0x5f 0x45 0x23 0x02 0x60 0x38 0x23 0x02 0x61 0x35 0x23 0x02 0x62 0x27 0x23 0x02 0x63 0x2d 0x23 0x02 0x64 0x18 0x23 0x02 0x65 0x33 0x23 0x02 0x66 0x34 0x23 0x02 0x67 0x35 0x23 0x02 0x68 0x56 0x23 0x02 0x69 0x45 0x23 0x02 0x6a 0x4f 0x23 0x02 0x6b 0x42 0x23 0x02 0x6c 0x40 0x23 0x02 0x6d 0x34 0x23 0x02 0x6e 0x25 0x23 0x02 0x6f 0x02 0x23 0x02 0x70 0x77 0x23 0x02 0x71 0x56 0x23 0x02 0x72 0x45 0x23 0x02 0x73 0x38 0x23 0x02 0x74 0x35 0x23 0x02 0x75 0x27 0x23 0x02 0x76 0x2d 0x23 0x02 0x77 0x18 0x23 0x02 0x78 0x33 0x23 0x02 0x79 0x34 0x23 0x02 0x7a 0x35 0x23 0x02 0x7b 0x56 0x23 0x02 0x7c 0x45 0x23 0x02 0x7d 0x4f 0x23 0x02 0x7e 0x42 0x23 0x02 0x7f 0x40 0x23 0x02 0x80 0x34 0x23 0x02 0x81 0x25 0x23 0x02 0x82 0x02 0x23 0x02 0xe0 0x02 0x23 0x02 0x00 0x53 0x23 0x02 0x01 0x55 0x23 0x02 0x02 0x55 0x23 0x02 0x03 0x51 0x23 0x02 0x04 0x77 0x23 0x02 0x05 0x57 0x23 0x02 0x06 0x1f 0x23 0x02 0x07 0x4f 0x23 0x02 0x08 0x4d 0x23 0x02 0x09 0x1f 0x23 0x02 0x0a 0x4b 0x23 0x02 0x0b 0x49 0x23 0x02 0x0c 0x1f 0x23 0x02 0x0d 0x47 0x23 0x02 0x0e 0x45 0x23 0x02 0x0f 0x41 0x23 0x02 0x10 0x1f 0x23 0x02 0x11 0x1f 0x23 0x02 0x12 0x1f 0x23 0x02 0x13 0x55 0x23 0x02 0x14 0x1f 0x23 0x02 0x15 0x1f 0x23 0x02 0x16 0x52 0x23 0x02 0x17 0x55 0x23 0x02 0x18 0x55 0x23 0x02 0x19 0x50 0x23 0x02 0x1a 0x77 0x23 0x02 0x1b 0x57 0x23 0x02 0x1c 0x1f 0x23 0x02 0x1d 0x4e 0x23 0x02 0x1e 0x4c 0x23 0x02 0x1f 0x1f 0x23 0x02 0x20 0x4a 0x23 0x02 0x21 0x48 0x23 0x02 0x22 0x1f 0x23 0x02 0x23 0x46 0x23 0x02 0x24 0x44 0x23 0x02 0x25 0x40 0x23 0x02 0x26 0x1f 0x23 0x02 0x27 0x1f 0x23 0x02 0x28 0x1f 0x23 0x02 0x29 0x1f 0x23 0x02 0x2a 0x1f 0x23 0x02 0x2b 0x55 0x23 0x02 0x2c 0x12 0x23 0x02 0x2d 0x15 0x23 0x02 0x2e 0x15 0x23 0x02 0x2f 0x00 0x23 0x02 0x30 0x37 0x23 0x02 0x31 0x17 0x23 0x02 0x32 0x1f 0x23 0x02 0x33 0x08 0x23 0x02 0x34 0x0a 0x23 0x02 0x35 0x1f 0x23 0x02 0x36 0x0c 0x23 0x02 0x37 0x0e 0x23 0x02 0x38 0x1f 0x23 0x02 0x39 0x04 0x23 0x02 0x3a 0x06 0x23 0x02 0x3b 0x10 0x23 0x02 0x3c 0x1f 0x23 0x02 0x3d 0x1f 0x23 0x02 0x3e 0x1f 0x23 0x02 0x3f 0x15 0x23 0x02 0x40 0x1f 0x23 0x02 0x41 0x1f 0x23 0x02 0x42 0x13 0x23 0x02 0x43 0x15 0x23 0x02 0x44 0x15 0x23 0x02 0x45 0x01 0x23 0x02 0x46 0x37 0x23 0x02 0x47 0x17 0x23 0x02 0x48 0x1f 0x23 0x02 0x49 0x09 0x23 0x02 0x4a 0x0b 0x23 0x02 0x4b 0x1f 0x23 0x02 0x4c 0x0d 0x23 0x02 0x4d 0x0f 0x23 0x02 0x4e 0x1f 0x23 0x02 0x4f 0x05 0x23 0x02 0x50 0x07 0x23 0x02 0x51 0x11 0x23 0x02 0x52 0x1f 0x23 0x02 0x53 0x1f 0x23 0x02 0x54 0x1f 0x23 0x02 0x55 0x1f 0x23 0x02 0x56 0x1f 0x23 0x02 0x57 0x15 0x23 0x02 0x58 0x40 0x23 0x02 0x59 0x00 0x23 0x02 0x5a 0x00 0x23 0x02 0x5b 0x10 0x23 0x02 0x5c 0x14 0x23 0x02 0x5d 0x40 0x23 0x02 0x5e 0x01 0x23 0x02 0x5f 0x02 0x23 0x02 0x60 0x40 0x23 0x02 0x61 0x03 0x23 0x02 0x62 0x04 0x23 0x02 0x63 0x7a 0x23 0x02 0x64 0x7a 0x23 0x02 0x65 0x74 0x23 0x02 0x66 0x16 0x23 0x02 0x67 0xb4 0x23 0x02 0x68 0x16 0x23 0x02 0x69 0x7a 0x23 0x02 0x6a 0x7a 0x23 0x02 0x6b 0x0c 0x23 0x02 0x6c 0x00 0x23 0x02 0x6d 0x04 0x23 0x02 0x6e 0x04 0x23 0x02 0x6f 0x88 0x23 0x02 0x70 0x00 0x23 0x02 0x71 0x00 0x23 0x02 0x72 0x06 0x23 0x02 0x73 0x7b 0x23 0x02 0x74 0x00 0x23 0x02 0x75 0xbc 0x23 0x02 0x76 0x00 0x23 0x02 0x77 0x04 0x23 0x02 0x78 0x2c 0x23 0x02 0x79 0x00 0x23 0x02 0x7a 0x00 0x23 0x02 0x7b 0x00 0x23 0x02 0x7c 0x00 0x23 0x02 0x7d 0x03 0x23 0x02 0x7e 0x7b 0x23 0x02 0xe0 0x04 0x23 0x02 0x09 0x11 0x23 0x02 0x0e 0x48 0x23 0x02 0x2b 0x2b 0x23 0x02 0x2e 0x44 0x23 0x02 0xe0 0x00 0x23 0x02 0xe6 0x02 0x23 0x02 0xe7 0x0c 0x05 0x01 0x11 0xfd 0x01 0x78 0x05 0x01 0x29 0x05 0x01 0x35 0xfd 0x01 0x14 0xff 0x00>;
			init_off = <0x05 0x01 0x28 0xfd 0x01 0x0a 0x05 0x01 0x10 0xfd 0x01 0x96 0xff 0x00>;
		};

		extern_6 {
			index = <0x06>;
			extern_name = "mipi_default";
			status = "okay";
			type = <0x02>;
			cmd_size = <0xff>;
			init_on = <0x15 0x02 0x80 0xac 0x15 0x02 0x81 0xb8 0x15 0x02 0x82 0x09 0x15 0x02 0x83 0x78 0x15 0x02 0x84 0x7f 0x15 0x02 0x85 0xbb 0x15 0x02 0x86 0x70 0xff 0x28 0xff 0xff>;
			init_off = <0xff 0xc8 0xff 0xff>;
		};

		extern_7 {
			index = <0x07>;
			extern_name = "ext_default";
			status = "okay";
			type = <0x00>;
			i2c_address = <0x48>;
			i2c_second_address = <0x49>;
			cmd_size = <0xff>;
			init_on = <0xc0 0x02 0x08 0xff 0xc0 0x02 0x09 0xff 0xc0 0x02 0x0a 0xff 0xc0 0x02 0x0b 0x7c 0xc0 0x02 0x0c 0xff 0xfd 0x01 0x0a 0xc0 0x02 0x31 0xa1 0xc0 0x02 0x32 0xa1 0xc0 0x02 0x33 0x03 0xc0 0x02 0x37 0x00 0xc0 0x02 0x38 0x22 0xc0 0x02 0x60 0x82 0xfd 0x01 0x0a 0xc0 0x02 0x39 0x45 0xc0 0x02 0x3b 0x00 0xfd 0x01 0x0a 0xc0 0x02 0x44 0x31 0xc0 0x02 0x55 0x44 0xc0 0x02 0x57 0x01 0xc0 0x02 0x5a 0x02 0xfd 0x01 0x0a 0xc0 0x02 0x3e 0xc6 0xc0 0x02 0x41 0x7c 0xfd 0x01 0x0a 0xc1 0x02 0x10 0x04 0xc1 0x02 0x11 0x04 0xc1 0x02 0x12 0x04 0xc1 0x02 0x13 0x00 0xc1 0x02 0x14 0x00 0xc1 0x02 0x15 0x00 0xc1 0x02 0x1a 0x03 0xc1 0x02 0x1b 0x03 0xfd 0x01 0x14 0xc1 0x02 0x18 0x28 0xc1 0x02 0x19 0x05 0xc1 0x02 0x1c 0x00 0xc1 0x02 0x1d 0x05 0xc1 0x02 0x2f 0x0c 0xc1 0x02 0x34 0x72 0xc1 0x02 0x35 0x06 0xc1 0x02 0x36 0xee 0xc1 0x02 0x37 0x02 0xc1 0x02 0x38 0x14 0xc1 0x02 0x39 0x00 0xc1 0x02 0x3a 0x05 0xc1 0x02 0x3b 0x00 0xc1 0x02 0x3c 0xdc 0xc1 0x02 0x3d 0x00 0xc1 0x02 0x3e 0x6e 0xc1 0x02 0x3f 0x00 0xfd 0x01 0x0a 0xc0 0x02 0x03 0x7f 0xfd 0x01 0xc8 0xc0 0x02 0x03 0xff 0xfd 0x01 0xc8 0xc1 0x02 0x4e 0x6a 0xc1 0x02 0x4f 0x4d 0xc1 0x02 0x50 0xf3 0xc1 0x02 0x51 0x80 0xc1 0x02 0x1f 0x90 0xc1 0x02 0x20 0x01 0xc1 0x02 0x21 0x68 0xc1 0x02 0x22 0x01 0xc1 0x02 0x23 0x5e 0xc1 0x02 0x24 0x01 0xc1 0x02 0x25 0x54 0xc1 0x02 0x26 0x01 0xc1 0x02 0x27 0x90 0xc1 0x02 0x28 0x01 0xc1 0x02 0x29 0x68 0xc1 0x02 0x2a 0x01 0xc1 0x02 0x2b 0x5e 0xc1 0x02 0x2c 0x01 0xc1 0x02 0x2d 0x54 0xc1 0x02 0x2e 0x01 0xc1 0x02 0x42 0x64 0xc1 0x02 0x43 0x00 0xc1 0x02 0x44 0x04 0xc1 0x02 0x45 0x00 0xc1 0x02 0x46 0x59 0xc1 0x02 0x47 0x00 0xc1 0x02 0x48 0xf2 0xc1 0x02 0x49 0x06 0xc1 0x02 0x4a 0x00 0xc1 0x02 0x4b 0x72 0xc1 0x02 0x4c 0x45 0xc1 0x02 0x4d 0x00 0xc1 0x02 0x52 0x08 0xc1 0x02 0x53 0x00 0xc1 0x02 0x54 0xb2 0xc1 0x02 0x55 0x00 0xc1 0x02 0x56 0xe4 0xc1 0x02 0x57 0x0d 0xc1 0x02 0x58 0x00 0xc1 0x02 0x59 0xe4 0xc1 0x02 0x5a 0x8a 0xc1 0x02 0x5b 0x00 0xc1 0x02 0x5c 0x34 0xc1 0x02 0x1e 0x4f 0xc1 0x02 0x51 0x00 0xff 0x00>;
			init_off = <0xff 0x00>;
		};
	};

	backlight {
		compatible = "amlogic, backlight-sm1";
		status = "okay";
		key_valid = <0x00>;
		pinctrl-names = "pwm_on";
		pinctrl-0 = <0x63>;
		pinctrl_version = <0x02>;
		bl_pwm_config = <0x64>;
		bl-gpios = <0x18 0x16 0x00>;
		bl_gpio_names = "GPIOH_5";

		backlight_0 {
			index = <0x00>;
			bl_name = "backlight_pwm";
			bl_level_default_uboot_kernel = <0x64 0x64>;
			bl_level_attr = <0xff 0x0a 0x80 0x80>;
			bl_ctrl_method = <0x01>;
			bl_pwm_port = "PWM_F";
			bl_pwm_attr = <0x01 0x61a8 0x64 0x19>;
			bl_pwm_power = <0x00 0x00 0x0a 0x0a>;
			bl_pwm_en_sequence_reverse = <0x00>;
		};

		backlight_1 {
			index = <0x01>;
			bl_name = "bl_extern";
			bl_level_default_uboot_kernel = <0x64 0x64>;
			bl_level_attr = <0xff 0x0a 0x80 0x80>;
			bl_ctrl_method = <0x04>;
			bl_power_attr = <0x01 0x01 0x00 0xc8 0xc8>;
			bl_extern_index = <0x00>;
		};
	};

	bl_pwm_conf {
		phandle = <0x64>;

		pwm_channel_0 {
			pwm_port_index = <0x05>;
			pwms = <0x65 0x01 0x7558 0x00>;
		};
	};

	bl_extern {
		compatible = "amlogic, bl_extern";
		status = "disabled";
		i2c_bus = "i2c_bus_3";

		extern_0 {
			index = <0x00>;
			extern_name = "i2c_lp8556";
			type = <0x00>;
			i2c_address = <0x2c>;
			dim_max_min = <0xff 0x0a>;
		};

		extern_1 {
			index = <0x01>;
			extern_name = "mipi_lt070me05";
			type = <0x02>;
			dim_max_min = <0xff 0x0a>;
		};
	};

	aliases {
		serial0 = "/soc/aobus@ff800000/serial@3000";
		serial1 = "/serial@ffd24000";
		serial2 = "/serial@ffd23000";
		serial3 = "/serial@ffd22000";
		serial4 = "/soc/aobus@ff800000/serial@4000";
		tsensor0 = "/p_tsensor@ff634800";
		tsensor1 = "/d_tsensor@ff634c00";
		i2c0 = "/soc/cbus@ffd00000/i2c@1f000";
		i2c1 = "/soc/cbus@ffd00000/i2c@1e000";
		i2c2 = "/soc/cbus@ffd00000/i2c@1d000";
		i2c3 = "/soc/cbus@ffd00000/i2c@1c000";
		i2c4 = "/soc/aobus@ff800000/i2c@5000";
	};

	memory@00000000 {
		device_type = "memory";
		linux,usable-memory = <0x00 0x00 0x00 0x80000000>;
	};

	reserved-memory {
		#address-cells = <0x02>;
		#size-cells = <0x02>;
		ranges;

		ramoops@0x07400000 {
			compatible = "ramoops";
			reg = <0x00 0x7400000 0x00 0x100000>;
			record-size = <0x20000>;
			console-size = <0x40000>;
			ftrace-size = <0x80000>;
			pmsg-size = <0x20000>;
		};

		linux,secmon {
			compatible = "shared-dma-pool";
			reusable;
			size = <0x00 0x400000>;
			alignment = <0x00 0x400000>;
			alloc-ranges = <0x00 0x5000000 0x00 0x400000>;
			phandle = <0x0f>;
		};

		linux,secos {
			status = "disable";
			compatible = "amlogic, aml_secos_memory";
			reg = <0x00 0x5300000 0x00 0x2000000>;
			no-map;
			phandle = <0x12c>;
		};

		linux,meson-fb {
			compatible = "shared-dma-pool";
			reusable;
			size = <0x00 0x800000>;
			alignment = <0x00 0x400000>;
			alloc-ranges = <0x00 0x7f800000 0x00 0x800000>;
			phandle = <0x38>;
		};

		linux,ion-dev {
			compatible = "shared-dma-pool";
			reusable;
			size = <0x00 0x8000000>;
			alignment = <0x00 0x400000>;
			phandle = <0x1c>;
		};

		linux,di_cma {
			compatible = "shared-dma-pool";
			status = "disable";
			reusable;
			size = <0x00 0x00>;
			alignment = <0x00 0x400000>;
			phandle = <0x6d>;
		};

		linux,ppmgr {
			compatible = "shared-dma-pool";
			size = <0x00 0x00>;
			phandle = <0x6c>;
		};

		linux,codec_mm_cma {
			compatible = "shared-dma-pool";
			reusable;
			size = <0x00 0x1b000000>;
			alignment = <0x00 0x400000>;
			linux,contiguous-region;
			phandle = <0x69>;
		};

		linux,codec_mm_reserved {
			compatible = "amlogic, codec-mm-reserved";
			size = <0x00 0x00>;
			alignment = <0x00 0x100000>;
			phandle = <0x6a>;
		};

		linux,vdin1_cma {
			compatible = "shared-dma-pool";
			reusable;
			size = <0x00 0x1000000>;
			alignment = <0x00 0x400000>;
			phandle = <0x37>;
		};

		linux,vm0_cma {
			compatible = "shared-dma-pool";
			reusable;
			size = <0x00 0x2000000>;
			alignment = <0x00 0x400000>;
			phandle = <0x6f>;
		};
	};

	cma_shrinker {
		compatible = "amlogic, cma-shrinker";
		status = "okay";
		adj = <0x00 0x64 0xc8 0xfa 0x384 0x3b6>;
		free = <0x2000 0x3000 0x4000 0x6000 0x7000 0x8000>;
	};

	dummy-battery {
		compatible = "amlogic, dummy-battery";
		status = "disabled";
		phandle = <0x12d>;
	};

	dummy-charger {
		compatible = "amlogic, dummy-charger";
		status = "disabled";
		phandle = <0x12e>;
	};

	gpioleds {
		compatible = "gpio-leds";
		status = "disabled";

		net_red {
			label = "net_red";
			default-state = "on";
		};

		net_green {
			label = "net_green";
			default-state = "on";
		};

		remote_led {
			label = "remote_led";
			gpios = <0x66 0x0a 0x01>;
			default-state = "off";
			linux,default-trigger = "rc_feedback";
		};

		sys_led {
			label = "sys_led";
			gpios = <0x66 0x0b 0x01>;
			default-state = "on";
		};
	};

	cvbsout {
		compatible = "amlogic, cvbsout-sm1";
		dev_name = "cvbsout";
		status = "okay";
		clocks = <0x02 0x55 0x02 0x4e 0x02 0x4f 0x02 0x57>;
		clock-names = "venci_top_gate\0venci_0_gate\0venci_1_gate\0vdac_clk_gate";
		clk_path = <0x00>;
		performance = <0x1bf0 0x09 0x1b56 0x333 0x1b12 0x8080 0x1b05 0xfd 0x1c59 0xf850 0xffff 0x00>;
		performance_sarft = <0x1bf0 0x09 0x1b56 0x333 0x1b12 0x00 0x1b05 0x09 0x1c59 0xfc48 0xffff 0x00>;
		performance_revB_telecom = <0x1bf0 0x09 0x1b56 0x546 0x1b12 0x8080 0x1b05 0x09 0x1c59 0xf850 0xffff 0x00>;
	};

	bt-dev {
		compatible = "amlogic, bt-dev";
		dev_name = "bt-dev";
		status = "okay";
		gpio_reset = <0x18 0x53 0x00>;
		gpio_hostwake = <0x18 0x55 0x00>;
	};

	wifi {
		compatible = "amlogic, aml_wifi";
		dev_name = "aml_wifi";
		status = "okay";
		interrupt_pin = <0x18 0x49 0x00>;
		irq_trigger_type = "GPIO_IRQ_LOW";
		power_on_pin = <0x18 0x48 0x00>;
		dhd_static_buf;
		pinctrl-names = "default";
		pinctrl-0 = <0x67>;
		pwm_config = <0x68>;
	};

	wifi_pwm_conf {
		phandle = <0x68>;

		pwm_channel1_conf {
			pwms = <0x65 0x00 0x774d 0x00>;
			duty-cycle = <0x3ba6>;
			times = <0x0a>;
		};

		pwm_channel2_conf {
			pwms = <0x65 0x02 0x7724 0x00>;
			duty-cycle = <0x3b92>;
			times = <0x0c>;
		};
	};

	codec_mm {
		compatible = "amlogic, codec, mm";
		memory-region = <0x69 0x6a>;
		dev_name = "codec_mm";
		status = "okay";
	};

	linux,picdec {
		compatible = "shared-dma-pool";
		reusable;
		size = <0x00>;
		alignment = <0x00>;
		linux,contiguous-region;
		phandle = <0x6b>;
	};

	picdec {
		compatible = "amlogic, picdec";
		memory-region = <0x6b>;
		dev_name = "picdec";
		status = "okay";
	};

	ppmgr {
		compatible = "amlogic, ppmgr";
		memory-region = <0x6c>;
		dev_name = "ppmgr";
		status = "okay";
	};

	multi-di {
		compatible = "amlogic, dim-sm1";
		status = "okay";
		flag_cma = <0x04>;
		memory-region = <0x6d>;
		interrupts = <0x00 0x2e 0x01 0x00 0x28 0x01>;
		interrupt-names = "pre_irq\0post_irq";
		clocks = <0x02 0x9b 0x02 0x9c>;
		clock-names = "vpu_clkb_tmp_composite\0vpu_clkb_composite";
		clock-range = <0x14e 0x29b>;
		buffer-size = <0x3e2c40>;
		post-wr-support = <0x01>;
		nr10bit-support = <0x01>;
		nrds-enable = <0x01>;
		pps-enable = <0x01>;
	};

	deinterlace {
		compatible = "amlogic, deinterlace";
		status = "disable";
		flag_cma = <0x01>;
		interrupts = <0x00 0x2e 0x01 0x00 0x28 0x01>;
		interrupt-names = "pre_irq\0post_irq";
		clocks = <0x02 0x9b 0x02 0x9c>;
		clock-names = "vpu_clkb_tmp_composite\0vpu_clkb_composite";
		clock-range = <0x14e 0x29b>;
		buffer-size = <0x3e2c40>;
		post-wr-support = <0x01>;
		nr10bit-support = <0x01>;
		nrds-enable = <0x01>;
		pps-enable = <0x01>;
	};

	dvb {
		compatible = "amlogic, dvb-demux";
		dev_name = "dvb";
		status = "okay";
		dtv_demod0_i2c_adap = <0x6e>;
		dtv_demod0_reset_gpio = <0x18 0x0b 0x00>;
		dtv_demod0_reset_value = <0x00>;
		dtv_demod0_ant_power_gpio = <0x18 0x16 0x00>;
		dtv_demod1_i2c_adap = <0x6e>;
		dtv_demod1_reset_gpio = <0x18 0x0b 0x00>;
		dtv_demod1_reset_value = <0x00>;
		interrupts = <0x00 0x17 0x01 0x00 0x05 0x01 0x00 0x35 0x01 0x00 0x13 0x01 0x00 0x19 0x01 0x00 0x12 0x01 0x00 0x18 0x01>;
		interrupt-names = "demux0_irq\0demux1_irq\0demux2_irq\0dvr0_irq\0dvr1_irq\0dvrfill0_fill\0dvrfill1_flush";
		clocks = <0x02 0x39 0x02 0x43 0x02 0x40>;
		clock-names = "demux\0ahbarb0\0parser_top";
		ewbs_alert_value = <0x01>;
		ewbs_alert_gpio = <0x66 0x04 0x00>;
		phandle = <0x12f>;
	};

	ionvideo {
		compatible = "amlogic, ionvideo";
		dev_name = "ionvideo";
		status = "okay";
	};

	amlvideo2_0 {
		compatible = "amlogic, amlvideo2";
		dev_name = "amlvideo2";
		status = "okay";
		amlvideo2_id = <0x00>;
		cma_mode = <0x01>;
	};

	amlvideo2_1 {
		compatible = "amlogic, amlvideo2";
		dev_name = "amlvideo2";
		status = "okay";
		amlvideo2_id = <0x01>;
		cma_mode = <0x01>;
	};

	vm0 {
		compatible = "amlogic, vm";
		memory-region = <0x6f>;
		dev_name = "vm0";
		status = "disabled";
		vm_id = <0x00>;
	};

	amvdec_656in {
		compatible = "amlogic, amvdec_656in";
		dev_name = "amvdec_656in";
		status = "disabled";
		reg = <0x00 0xffe02000 0x00 0x7c>;
		clocks = <0x02 0xcd 0x02 0x48>;
		clock-names = "cts_bt656_clk1\0clk_gate_bt656";

		bt656in1 {
			bt656_id = <0x01>;
			status = "disabled";
		};
	};

	aml_cams {
		compatible = "amlogic, cams_prober";
		status = "disabled";
		pinctrl-names = "default";
		pinctrl-0 = <0x70 0x71>;
		clocks = <0x02 0xdc>;
		clock-names = "g12a_24m";

		cam_0 {
			cam_name = "gc2145";
			front_back = <0x00>;
			camera-i2c-bus = <0x72>;
			gpio_pwdn-gpios = <0x18 0x03 0x00>;
			gpio_rst-gpios = <0x18 0x0d 0x00>;
			mirror_flip = <0x01>;
			vertical_flip = <0x01>;
			spread_spectrum = <0x00>;
			bt_path = "gpio";
			bt_path_count = <0x01>;
			vdin_path = <0x00>;
			status = "okay";
		};
	};

	sysled {
		compatible = "amlogic, sysled";
		dev_name = "sysled";
		status = "okay";
		led_gpio = <0x66 0x0b 0x00>;
	};

	gpio_keypad {
		compatible = "amlogic, gpio_keypad";
		status = "okay";
		scan_period = <0x14>;
		key_num = <0x01>;
		key_name = "NES_RESET_CLICK";
		key_code = <0x281>;
		key-gpios = <0x66 0x03 0x00>;
		interrupts = <0x00 0x46 0x01 0x00 0x47 0x02>;
		interrupt-names = "irq_keyup\0irq_keydown";
		detect_mode = <0x00>;
	};

	unifykey {
		compatible = "amlogic, unifykey";
		status = "ok";
		unifykey-num = <0x2d>;
		unifykey-index-0 = <0x73>;
		unifykey-index-1 = <0x74>;
		unifykey-index-2 = <0x75>;
		unifykey-index-3 = <0x76>;
		unifykey-index-4 = <0x77>;
		unifykey-index-5 = <0x78>;
		unifykey-index-6 = <0x79>;
		unifykey-index-7 = <0x7a>;
		unifykey-index-8 = <0x7b>;
		unifykey-index-9 = <0x7c>;
		unifykey-index-10 = <0x7d>;
		unifykey-index-11 = <0x7e>;
		unifykey-index-12 = <0x7f>;
		unifykey-index-13 = <0x80>;
		unifykey-index-14 = <0x81>;
		unifykey-index-15 = <0x82>;
		unifykey-index-16 = <0x83>;
		unifykey-index-17 = <0x84>;
		unifykey-index-18 = <0x85>;
		unifykey-index-19 = <0x86>;
		unifykey-index-20 = <0x87>;
		unifykey-index-21 = <0x88>;
		unifykey-index-22 = <0x89>;
		unifykey-index-23 = <0x8a>;
		unifykey-index-24 = <0x8b>;
		unifykey-index-25 = <0x8c>;
		unifykey-index-26 = <0x8d>;
		unifykey-index-27 = <0x8e>;
		unifykey-index-28 = <0x8f>;
		unifykey-index-29 = <0x90>;
		unifykey-index-30 = <0x91>;
		unifykey-index-31 = <0x92>;
		unifykey-index-32 = <0x93>;
		unifykey-index-33 = <0x94>;
		unifykey-index-34 = <0x95>;
		unifykey-index-35 = <0x96>;
		unifykey-index-36 = <0x97>;
		unifykey-index-37 = <0x98>;
		unifykey-index-38 = <0x99>;
		unifykey-index-39 = <0x9a>;
		unifykey-index-40 = <0x9b>;
		unifykey-index-41 = <0x9c>;
		unifykey-index-42 = <0x9d>;
		unifykey-index-43 = <0x9e>;
		unifykey-index-44 = <0x9f>;

		key_0 {
			key-name = "usid";
			key-device = "normal";
			key-permit = "read\0write\0del";
			phandle = <0x73>;
		};

		key_1 {
			key-name = "mac";
			key-device = "normal";
			key-permit = "read\0write\0del";
			phandle = <0x74>;
		};

		key_2 {
			key-name = "hdcp";
			key-device = "secure";
			key-type = "sha1";
			key-permit = "read\0write\0del";
			phandle = <0x75>;
		};

		key_3 {
			key-name = "secure_boot_set";
			key-device = "efuse";
			key-permit = "write";
			phandle = <0x76>;
		};

		key_4 {
			key-name = "mac_bt";
			key-device = "normal";
			key-permit = "read\0write\0del";
			key-type = "mac";
			phandle = <0x77>;
		};

		key_5 {
			key-name = "mac_wifi";
			key-device = "normal";
			key-permit = "read\0write\0del";
			key-type = "mac";
			phandle = <0x78>;
		};

		key_6 {
			key-name = "hdcp2_tx";
			key-device = "normal";
			key-permit = "read\0write\0del";
			phandle = <0x79>;
		};

		key_7 {
			key-name = "hdcp2_rx";
			key-device = "normal";
			key-permit = "read\0write\0del";
			phandle = <0x7a>;
		};

		key_8 {
			key-name = "widevinekeybox";
			key-device = "secure";
			key-permit = "read\0write\0del";
			phandle = <0x7b>;
		};

		key_9 {
			key-name = "deviceid";
			key-device = "normal";
			key-permit = "read\0write\0del";
			phandle = <0x7c>;
		};

		key_10 {
			key-name = "hdcp22_fw_private";
			key-device = "secure";
			key-permit = "read\0write\0del";
			phandle = <0x7d>;
		};

		key_11 {
			key-name = "PlayReadykeybox25";
			key-device = "secure";
			key-permit = "read\0write\0del";
			phandle = <0x7e>;
		};

		key_12 {
			key-name = "prpubkeybox";
			key-device = "secure";
			key-permit = "read\0write\0del";
			phandle = <0x7f>;
		};

		key_13 {
			key-name = "prprivkeybox";
			key-device = "secure";
			key-permit = "read\0write\0del";
			phandle = <0x80>;
		};

		key_14 {
			key-name = "attestationkeybox";
			key-device = "secure";
			key-permit = "read\0write\0del";
			phandle = <0x81>;
		};

		key_15 {
			key-name = "region_code";
			key-device = "normal";
			key-permit = "read\0write\0del";
			phandle = <0x82>;
		};

		key_16 {
			key-name = "netflix_mgkid";
			key-device = "secure";
			key-permit = "read\0write\0del";
			phandle = <0x83>;
		};

		key_17 {
			key-name = "attestationdevidbox";
			key-device = "secure";
			key-permit = "read\0write\0del";
			phandle = <0x84>;
		};

		key_18 {
			key-name = "oemkey";
			key-device = "normal";
			key-permit = "read\0write\0del";
			phandle = <0x85>;
		};

		key_19 {
			key-name = "KEY_WIDEVINE";
			key-device = "provision";
			key-permit = "read\0write\0del";
			phandle = <0x86>;
		};

		key_20 {
			key-name = "KEY_PLAYREADY_PRIVATE";
			key-device = "provision";
			key-permit = "read\0write\0del";
			phandle = <0x87>;
		};

		key_21 {
			key-name = "KEY_PLAYREADY_PUBLIC";
			key-device = "provision";
			key-permit = "read\0write\0del";
			phandle = <0x88>;
		};

		key_22 {
			key-name = "KEY_HDCP_TX14";
			key-device = "provision";
			key-permit = "read\0write\0del";
			phandle = <0x89>;
		};

		key_23 {
			key-name = "KEY_HDCP_TX22";
			key-device = "provision";
			key-permit = "read\0write\0del";
			phandle = <0x8a>;
		};

		key_24 {
			key-name = "KEY_HDCP_RX14";
			key-device = "provision";
			key-permit = "read\0write\0del";
			phandle = <0x8b>;
		};

		key_25 {
			key-name = "KEY_HDCP_RX22";
			key-device = "provision";
			key-permit = "read\0write\0del";
			phandle = <0x8c>;
		};

		key_26 {
			key-name = "UUID";
			key-device = "normal";
			key-permit = "read\0write\0del";
			phandle = <0x8d>;
		};

		key_27 {
			key-name = "SERIALNO";
			key-device = "normal";
			key-permit = "read\0write\0del";
			phandle = <0x8e>;
		};

		key_28 {
			key-name = "OrderId";
			key-device = "normal";
			key-permit = "read\0write\0del";
			phandle = <0x8f>;
		};

		key_29 {
			key-name = "DID";
			key-device = "normal";
			key-permit = "read\0write\0del";
			phandle = <0x90>;
		};

		key_30 {
			key-name = "hdcp2lc128";
			key-device = "normal";
			key-permit = "read\0write\0del";
			phandle = <0x91>;
		};

		key_31 {
			key-name = "hdcp2key";
			key-device = "normal";
			key-permit = "read\0write\0del";
			phandle = <0x92>;
		};

		key_32 {
			key-name = "wmac";
			key-device = "normal";
			key-permit = "read\0write\0del";
			phandle = <0x93>;
		};

		key_33 {
			key-name = "skywaykey";
			key-device = "normal";
			key-permit = "read\0write\0del";
			phandle = <0x94>;
		};

		key_34 {
			key-name = "IOT_CERT";
			key-device = "normal";
			key-permit = "read\0write\0del";
			phandle = <0x95>;
		};

		key_35 {
			key-name = "IOT_CERT";
			key-device = "normal";
			key-permit = "read\0write\0del";
			phandle = <0x96>;
		};

		key_36 {
			key-name = "IOT_PRIV";
			key-device = "normal";
			key-permit = "read\0write\0del";
			phandle = <0x97>;
		};

		key_37 {
			key-name = "sboxid";
			key-device = "normal";
			key-permit = "read\0write\0del";
			phandle = <0x98>;
		};

		key_38 {
			key-name = "ssn";
			key-device = "normal";
			key-permit = "read\0write\0del";
			phandle = <0x99>;
		};

		key_39 {
			key-name = "oem";
			key-device = "normal";
			key-permit = "read\0write\0del";
			phandle = <0x9a>;
		};

		key_40 {
			key-name = "copyright";
			key-device = "normal";
			key-permit = "read\0write\0del";
			phandle = <0x9b>;
		};

		key_41 {
			key-name = "amlogic_set";
			key-device = "efuse";
			key-permit = "write";
			phandle = <0x9c>;
		};

		key_42 {
			key-name = "OTP";
			key-device = "normal";
			key-permit = "read\0write\0del";
			phandle = <0x9d>;
		};

		key_43 {
			key-name = "factoryflag";
			key-device = "normal";
			key-permit = "read\0write\0del";
			phandle = <0x9e>;
		};

		key_44 {
			key-name = "KEY_PROVISION_XXX";
			key-device = "provision";
			key-permit = "read\0write\0del";
			phandle = <0x9f>;
		};
	};

	efusekey {
		keynum = <0x04>;
		key0 = <0xa0>;
		key1 = <0xa1>;
		key2 = <0xa2>;
		key3 = <0xa3>;
		phandle = <0x4b>;

		key_0 {
			keyname = "mac";
			offset = <0x00>;
			size = <0x06>;
			phandle = <0xa0>;
		};

		key_1 {
			keyname = "mac_bt";
			offset = <0x06>;
			size = <0x06>;
			phandle = <0xa1>;
		};

		key_2 {
			keyname = "mac_wifi";
			offset = <0x0c>;
			size = <0x06>;
			phandle = <0xa2>;
		};

		key_3 {
			keyname = "usid";
			offset = <0x12>;
			size = <0x10>;
			phandle = <0xa3>;
		};
	};

	amlvecm {
		compatible = "amlogic, vecm";
		dev_name = "aml_vecm";
		status = "okay";
		gamma_en = <0x00>;
		wb_en = <0x00>;
		cm_en = <0x00>;
		tx_op_color_primary = <0x00>;
	};

	amdolby_vision {
		compatible = "amlogic, dolby_vision_sm1";
		dev_name = "aml_amdolby_vision_driver";
		status = "okay";
		tv_mode = <0x00>;
	};

	dummy {
		#sound-dai-cells = <0x00>;
		compatible = "amlogic, aml_dummy_codec";
		status = "okay";
		phandle = <0xa5>;
	};

	t9015 {
		#sound-dai-cells = <0x00>;
		compatible = "amlogic, aml_codec_T9015";
		reg = <0x00 0xff632000 0x00 0x2000>;
		is_auge_used = <0x01>;
		tocodec_inout = <0x01>;
		tdmout_index = <0x01>;
		ch0_sel = <0x00>;
		ch1_sel = <0x01>;
		status = "okay";
		phandle = <0xa7>;
	};

	eqdrc {
		eqdrc_module = <0x01>;
		lane_mask = <0x01>;
		channel_mask = <0x03>;
		phandle = <0x130>;
	};

	auge_sound {
		compatible = "amlogic, g12a-sound-card";
		aml-audio-card,name = "AML-AUGESOUND";
		avout_mute-gpios = <0x66 0x02 0x00>;

		aml-audio-card,dai-link@0 {
			format = "dsp_a";
			mclk-fs = <0x200>;
			bitclock-master = <0xa4>;
			frame-master = <0xa4>;
			suffix-name = "alsaPORT-pcm";

			cpu {
				sound-dai = <0xa4>;
				dai-tdm-slot-tx-mask = <0x01 0x01 0x01 0x01 0x01 0x01 0x01 0x01>;
				dai-tdm-slot-rx-mask = <0x01 0x01 0x01 0x01 0x01 0x01 0x01 0x01>;
				dai-tdm-slot-num = <0x08>;
				dai-tdm-slot-width = <0x20>;
				system-clock-frequency = <0x1770000>;
				phandle = <0x131>;
			};

			codec {
				sound-dai = <0xa5 0xa5>;
				phandle = <0x132>;
			};
		};

		aml-audio-card,dai-link@1 {
			format = "i2s";
			mclk-fs = <0x100>;
			bitclock-master = <0xa6>;
			frame-master = <0xa6>;
			suffix-name = "alsaPORT-i2s";

			cpu {
				sound-dai = <0xa6>;
				dai-tdm-slot-tx-mask = <0x01 0x01>;
				dai-tdm-slot-rx-mask = <0x01 0x01>;
				dai-tdm-slot-num = <0x02>;
				dai-tdm-slot-width = <0x20>;
				system-clock-frequency = <0xbb8000>;
			};

			codec {
				sound-dai = <0xa5 0xa5 0xa7>;
				phandle = <0x133>;
			};
		};

		aml-audio-card,dai-link@2 {
			format = "i2s";
			mclk-fs = <0x100>;
			bitclock-master = <0xa8>;
			frame-master = <0xa8>;
			suffix-name = "alsaPORT-i2s2hdmi";

			cpu {
				sound-dai = <0xa8>;
				dai-tdm-slot-tx-mask = <0x01 0x01>;
				dai-tdm-slot-rx-mask = <0x01 0x01>;
				dai-tdm-slot-num = <0x02>;
				dai-tdm-slot-width = <0x20>;
				system-clock-frequency = <0xbb8000>;
			};

			codec {
				sound-dai = <0xa5>;
				phandle = <0x134>;
			};
		};

		aml-audio-card,dai-link@3 {
			mclk-fs = <0x40>;
			suffix-name = "alsaPORT-pdm-builtinmic";

			cpu {
				sound-dai = <0xa9>;
			};

			codec {
				sound-dai = <0xa5>;
			};
		};

		aml-audio-card,dai-link@4 {
			mclk-fs = <0x80>;
			continuous-clock;
			suffix-name = "alsaPORT-spdif";

			cpu {
				sound-dai = <0xaa>;
				system-clock-frequency = <0x5dc000>;
			};

			codec {
				sound-dai = <0xa5>;
			};
		};

		aml-audio-card,dai-link@5 {
			mclk-fs = <0x80>;
			continuous-clock;
			suffix-name = "alsaPORT-spdifb";

			cpu {
				sound-dai = <0xab>;
				system-clock-frequency = <0x5dc000>;
			};

			codec {
				sound-dai = <0xa5>;
			};
		};

		aml-audio-card,dai-link@6 {
			mclk-fs = <0x100>;
			suffix-name = "alsaPORT-earc";

			cpu {
				sound-dai = <0xac>;
				system-clock-frequency = <0xbb8000>;
			};

			codec {
				sound-dai = <0xa5>;
			};
		};

		aml-audio-card,dai-link@7 {
			mclk-fs = <0x100>;
			continuous-clock;
			suffix-name = "alsaPORT-loopback";

			cpu {
				sound-dai = <0xad>;
				system-clock-frequency = <0xbb8000>;
			};

			codec {
				sound-dai = <0xa5>;
			};
		};
	};

	locker {
		compatible = "amlogic, audiolocker";
		clocks = <0x1d 0x2d 0x1d 0x2e 0x1d 0x27 0x1d 0x28 0x02 0x0d 0x02 0x0e>;
		clock-names = "lock_out\0lock_in\0out_src\0in_src\0out_calc\0in_ref";
		interrupts = <0x00 0x01 0x01>;
		interrupt-names = "irq";
		frequency = <0x2ebae40>;
		dividor = <0x31>;
		status = "disabled";
		phandle = <0x135>;
	};

	cpu_opp_table0 {
		compatible = "operating-points-v2";
		opp-shared;
		phandle = <0x0d>;

		opp00 {
			opp-hz = <0x00 0x5f5e100>;
			opp-microvolt = <0xbbfd0>;
		};

		opp01 {
			opp-hz = <0x00 0xee6b280>;
			opp-microvolt = <0xbbfd0>;
		};

		opp02 {
			opp-hz = <0x00 0x1dcd6500>;
			opp-microvolt = <0xbbfd0>;
		};

		opp03 {
			opp-hz = <0x00 0x27c19cc0>;
			opp-microvolt = <0xc0df0>;
		};

		opp04 {
			opp-hz = <0x00 0x3b9aca00>;
			opp-microvolt = <0xc5c10>;
		};

		opp05 {
			opp-hz = <0x00 0x47868c00>;
			opp-microvolt = <0xc8320>;
		};

		opp06 {
			opp-hz = <0x00 0x53af5700>;
			opp-microvolt = <0xcaa30>;
		};

		opp07 {
			opp-hz = <0x00 0x59682f00>;
			opp-microvolt = <0xcd140>;
		};

		opp08 {
			opp-hz = <0x00 0x5fd82200>;
			opp-microvolt = <0xd4670>;
		};

		opp09 {
			opp-hz = <0x00 0x6590fa00>;
			opp-microvolt = <0xde2b0>;
		};

		opp10 {
			opp-hz = <0x00 0x6b49d200>;
			opp-microvolt = <0xe7ef0>;
		};

		opp11 {
			opp-hz = <0x00 0x71b9c500>;
			opp-microvolt = <0xf6950>;
		};
	};

	cpufreq-meson {
		compatible = "amlogic, cpufreq-meson";
		pinctrl-names = "default";
		pinctrl-0 = <0xae>;
		status = "okay";
	};

	__symbols__ {
		gpu = "/bifrost";
		dvfs125_cfg = "/bifrost/clk125_cfg";
		dvfs250_cfg = "/bifrost/dvfs250_cfg";
		dvfs285_cfg = "/bifrost/dvfs285_cfg";
		dvfs400_cfg = "/bifrost/dvfs400_cfg";
		dvfs500_cfg = "/bifrost/dvfs500_cfg";
		dvfs666_cfg = "/bifrost/dvfs666_cfg";
		dvfs800_cfg = "/bifrost/dvfs800_cfg";
		dvfs850_cfg = "/bifrost/dvfs850_cfg";
		cpus = "/cpus";
		cluster0 = "/cpus/cpu-map/cluster0";
		CPU0 = "/cpus/cpu@0";
		CPU1 = "/cpus/cpu@1";
		CPU2 = "/cpus/cpu@2";
		CPU3 = "/cpus/cpu@3";
		CPU_SLEEP_0 = "/cpus/idle-states/cpu-sleep-0";
		gic = "/interrupt-controller@2c001000";
		mailbox = "/mhu@c883c400";
		xtal = "/xtal-clk";
		vpu = "/vpu";
		ethmac = "/ethernet@ff3f0000";
		pinctrl_aobus = "/pinctrl@ff800014";
		gpio_ao = "/pinctrl@ff800014/ao-bank@ff800014";
		sd_to_ao_uart_clr_pins = "/pinctrl@ff800014/sd_to_ao_uart_clr_pins";
		sd_to_ao_uart_pins = "/pinctrl@ff800014/sd_to_ao_uart_pins";
		ao_uart_pins = "/pinctrl@ff800014/ao_uart";
		ao_b_uart_pins = "/pinctrl@ff800014/ao_b_uart";
		ao_i2c_master_pins1 = "/pinctrl@ff800014/ao_i2c_pins1";
		ao_i2c_master_pins2 = "/pinctrl@ff800014/ao_i2c_pins2";
		ao_i2c_slave_pins = "/pinctrl@ff800014/ao_i2c_slave_pins";
		pwm_ao_a_pins = "/pinctrl@ff800014/pwm_ao_a";
		pwm_ao_a_hiz_pins = "/pinctrl@ff800014/pwm_ao_a_hiz";
		pwm_ao_b_pins = "/pinctrl@ff800014/pwm_ao_b";
		pwm_ao_c_pins1 = "/pinctrl@ff800014/pwm_ao_c_pins1";
		pwm_ao_c_pins2 = "/pinctrl@ff800014/pwm_ao_c_pins2";
		pwm_ao_c_hiz_pins = "/pinctrl@ff800014/pwm_ao_c_hiz";
		pwm_ao_d_pins1 = "/pinctrl@ff800014/pwm_ao_d_pins1";
		pwm_ao_d_pins2 = "/pinctrl@ff800014/pwm_ao_d_pins2";
		pwm_ao_d_pins3 = "/pinctrl@ff800014/pwm_ao_d_pins3";
		aocec_a = "/pinctrl@ff800014/ao_ceca";
		aocec_b = "/pinctrl@ff800014/ao_cecb";
		jtag_apao_pins = "/pinctrl@ff800014/jtag_apao_pin";
		remote_pins = "/pinctrl@ff800014/remote_pin";
		irblaster_pins = "/pinctrl@ff800014/irblaster_pin";
		dvb_s_ts0_pins = "/pinctrl@ff800014/dvb_s_ts0_pins";
		pinctrl_periphs = "/pinctrl@ff634480";
		gpio = "/pinctrl@ff634480/banks@ff6346c0";
		emmc_clk_cmd_pins = "/pinctrl@ff634480/emmc_clk_cmd_pins";
		emmc_conf_pull_up = "/pinctrl@ff634480/emmc_conf_pull_up";
		emmc_conf_pull_done = "/pinctrl@ff634480/emmc_conf_pull_done";
		sd_clk_cmd_pins = "/pinctrl@ff634480/sd_clk_cmd_pins";
		sd_all_pins = "/pinctrl@ff634480/sd_all_pins";
		sd_all_pd_pins = "/pinctrl@ff634480/sd_all_pd_pins";
		sd_1bit_pins = "/pinctrl@ff634480/sd_1bit_pins";
		sd_clr_all_pins = "/pinctrl@ff634480/sd_clr_all_pins";
		sd_clr_noall_pins = "/pinctrl@ff634480/sd_clr_noall_pins";
		ao_to_sd_uart_pins = "/pinctrl@ff634480/ao_to_sd_uart_pins";
		sdio_clk_cmd_pins = "/pinctrl@ff634480/sdio_clk_cmd_pins";
		sdio_all_pins = "/pinctrl@ff634480/sdio_all_pins";
		sdio_x_clk_cmd_pins = "/pinctrl@ff634480/sdio_x_clk_cmd_pins";
		sdio_x_all_pins = "/pinctrl@ff634480/sdio_x_all_pins";
		sdio_x_en_pins = "/pinctrl@ff634480/sdio_x_en_pins";
		sdio_x_clr_pins = "/pinctrl@ff634480/sdio_x_clr_pins";
		all_nand_pins = "/pinctrl@ff634480/all_nand_pins";
		nand_cs_pins = "/pinctrl@ff634480/nand_cs";
		i2c0_master_pins1 = "/pinctrl@ff634480/i2c0_pins1";
		i2c0_master_pins2 = "/pinctrl@ff634480/i2c0_pins2";
		i2c0_master_pins3 = "/pinctrl@ff634480/i2c0_pins3";
		i2c1_master_pins1 = "/pinctrl@ff634480/i2c1_pins1";
		i2c1_master_pins2 = "/pinctrl@ff634480/i2c1_pins2";
		i2c1_master_pins3 = "/pinctrl@ff634480/i2c1_pins3";
		i2c2_master_pins1 = "/pinctrl@ff634480/i2c2_pins1";
		i2c2_master_pins2 = "/pinctrl@ff634480/i2c2_pins2";
		i2c2_master_pins3 = "/pinctrl@ff634480/i2c2_pins3";
		i2c3_master_pins1 = "/pinctrl@ff634480/i2c3_pins1";
		i2c3_master_pins2 = "/pinctrl@ff634480/i2c3_pins2";
		pwm_a_pins = "/pinctrl@ff634480/pwm_a";
		pwm_b_pins1 = "/pinctrl@ff634480/pwm_b_pins1";
		pwm_b_pins2 = "/pinctrl@ff634480/pwm_b_pins2";
		pwm_c_pins1 = "/pinctrl@ff634480/pwm_c_pins1";
		pwm_c_pins2 = "/pinctrl@ff634480/pwm_c_pins2";
		pwm_c_pins3 = "/pinctrl@ff634480/pwm_c_pins3";
		pwm_d_pins1 = "/pinctrl@ff634480/pwm_d_pins1";
		pwm_d_pins2 = "/pinctrl@ff634480/pwm_d_pins2";
		pwm_e_pins = "/pinctrl@ff634480/pwm_e";
		pwm_f_pins1 = "/pinctrl@ff634480/pwm_f_pins1";
		pwm_f_pins2 = "/pinctrl@ff634480/pwm_f_pins2";
		spicc0_pins_x = "/pinctrl@ff634480/spicc0_pins_x";
		spicc0_pins_c = "/pinctrl@ff634480/spicc0_pins_c";
		spicc1_pins = "/pinctrl@ff634480/spicc1_pins";
		a_uart_pins = "/pinctrl@ff634480/a_uart";
		b_uart_pins = "/pinctrl@ff634480/b_uart";
		c_uart_pins = "/pinctrl@ff634480/c_uart";
		hdmitx_hpd = "/pinctrl@ff634480/hdmitx_hpd";
		hdmitx_hpd_gpio = "/pinctrl@ff634480/hdmitx_hpd_gpio";
		hdmitx_ddc = "/pinctrl@ff634480/hdmitx_ddc";
		eecec_a = "/pinctrl@ff634480/ee_ceca";
		eecec_b = "/pinctrl@ff634480/ee_cecb";
		internal_eth_pins = "/pinctrl@ff634480/internal_eth_pins";
		internal_gpio_pins = "/pinctrl@ff634480/internal_gpio_pins";
		external_eth_pins = "/pinctrl@ff634480/external_eth_pins";
		jtag_apee_pins = "/pinctrl@ff634480/jtag_apee_pin";
		tdmout_a = "/pinctrl@ff634480/tdmout_a";
		tdmin_a = "/pinctrl@ff634480/tdmin_a";
		tdmb_mclk = "/pinctrl@ff634480/tdmb_mclk";
		tdmout_b = "/pinctrl@ff634480/tdmout_b";
		tdmin_b = "/pinctrl@ff634480/tdmin_b";
		tdmc_mclk = "/pinctrl@ff634480/tdmc_mclk";
		tdmout_c = "/pinctrl@ff634480/tdmout_c";
		tdmin_c = "/pinctrl@ff634480/tdmin_c";
		spdifin = "/pinctrl@ff634480/spdifin";
		pdmin = "/pinctrl@ff634480/pdmin";
		bl_pwm_off_pins = "/pinctrl@ff634480/bl_pwm_off_pin";
		clk12_24_z_pins = "/pinctrl@ff634480/clk12_24_z_pins";
		gen_clk_ee_z = "/pinctrl@ff634480/gen_clk_ee_z";
		cam_dvp_pins = "/pinctrl@ff634480/cam_dvp_pins";
		spdifout = "/pinctrl@ff634480/spdifout";
		dvb_s_ts1_pins = "/pinctrl@ff634480/dvb_s_ts1_pins";
		audio_data = "/audio_data";
		dwc3 = "/dwc3@ff500000";
		usb2_phy_v2 = "/usb2phy@ffe09000";
		usb3_phy_v2 = "/usb3phy@ffe09080";
		dwc2_a = "/dwc2_a@ff400000";
		wdt = "/watchdog@0xffd0f0d0";
		saradc = "/saradc";
		power_ctrl = "/power_ctrl@ff8000e8";
		bl40 = "/bl40";
		cbus = "/soc/cbus@ffd00000";
		gpio_intc = "/soc/cbus@ffd00000/interrupt-controller@f080";
		pwm_ab = "/soc/cbus@ffd00000/pwm@1b000";
		pwm_cd = "/soc/cbus@ffd00000/pwm@1a000";
		pwm_ef = "/soc/cbus@ffd00000/pwm@19000";
		i2c0 = "/soc/cbus@ffd00000/i2c@1f000";
		i2c1 = "/soc/cbus@ffd00000/i2c@1e000";
		i2c2 = "/soc/cbus@ffd00000/i2c@1d000";
		i2c3 = "/soc/cbus@ffd00000/i2c@1c000";
		ad82584f_62 = "/soc/cbus@ffd00000/i2c@1c000/ad82584f_62@62";
		spicc0 = "/soc/cbus@ffd00000/spi@13000";
		spicc1 = "/soc/cbus@ffd00000/spi@15000";
		aobus = "/soc/aobus@ff800000";
		aoclkc = "/soc/aobus@ff800000/clock-controller@0";
		pwm_AO_ab = "/soc/aobus@ff800000/pwm@7000";
		pwm_AO_cd = "/soc/aobus@ff800000/pwm@2000";
		i2c_AO = "/soc/aobus@ff800000/i2c@5000";
		i2c_AO_slave = "/soc/aobus@ff800000/i2c_slave@6000";
		uart_AO = "/soc/aobus@ff800000/serial@3000";
		uart_AO_B = "/soc/aobus@ff800000/serial@4000";
		irblaster = "/soc/aobus@ff800000/meson-irblaster@14c";
		periphs = "/soc/periphs@ff634400";
		hiubus = "/soc/hiubus@ff63c000";
		clkc = "/soc/hiubus@ff63c000/clock-controller@0";
		clkc_b = "/soc/hiubus@ff63c000/clock-controller@1";
		audiobus = "/soc/audiobus@0xFF660000";
		clkaudio = "/soc/audiobus@0xFF660000/audio_clocks";
		tdma = "/soc/audiobus@0xFF660000/tdm@0";
		tdmb = "/soc/audiobus@0xFF660000/tdm@1";
		tdmc = "/soc/audiobus@0xFF660000/tdm@2";
		tdmlb = "/soc/audiobus@0xFF660000/tdm@3";
		spdifa = "/soc/audiobus@0xFF660000/spdif@0";
		spdifb = "/soc/audiobus@0xFF660000/spdif@1";
		pdm = "/soc/audiobus@0xFF660000/pdm";
		asrca = "/soc/audiobus@0xFF660000/resample@0";
		vad = "/soc/audiobus@0xFF660000/vad";
		loopbacka = "/soc/audiobus@0xFF660000/loopback@0";
		loopbackb = "/soc/audiobus@0xFF660000/loopback@1";
		aed = "/soc/audiobus@0xFF660000/effect";
		audio_earc = "/soc/bus@ff663000";
		earc = "/soc/bus@ff663000/earc@0";
		remote = "/rc@0xff808040";
		custom_maps = "/custom_maps";
		map_0 = "/custom_maps/map_0";
		map_1 = "/custom_maps/map_1";
		map_2 = "/custom_maps/map_2";
		map_3 = "/custom_maps/map_3";
		map_4 = "/custom_maps/map_4";
		map_5 = "/custom_maps/map_5";
		uart_A = "/serial@ffd24000";
		uart_B = "/serial@ffd23000";
		uart_C = "/serial@ffd22000";
		pcie_A = "/pcieA@fc000000";
		amhdmitx = "/amhdmitx";
		vend_data = "/amhdmitx/vend_data";
		aocec = "/aocec";
		vdin0 = "/vdin0";
		vdin1 = "/vdin1";
		dummy_venc = "/dummy_venc";
		canvas = "/canvas";
		codec_io = "/codec_io";
		meson_fb = "/fb";
		sd_emmc_c = "/emmc@ffe07000";
		sd_emmc_b = "/sd@ffe05000";
		sd_emmc_a = "/sdio@ffe03000";
		nand = "/nfc@0";
		bootloader = "/nfc@0/bootloader";
		nandnormal = "/nfc@0/nandnormal";
		nand_partitions = "/nfc@0/nand_partition";
		vddcpu0 = "/pwmao_d-regulator";
		defendkey = "/defendkey";
		efuse = "/efuse";
		p_tsensor = "/p_tsensor@ff634800";
		d_tsensor = "/d_tsensor@ff634c00";
		meson_cooldev = "/meson-cooldev@0";
		cpufreq_cool0 = "/meson-cooldev@0/cpufreq_cool0";
		cpucore_cool0 = "/meson-cooldev@0/cpucore_cool0";
		gpufreq_cool0 = "/meson-cooldev@0/gpufreq_cool0";
		gpucore_cool0 = "/meson-cooldev@0/gpucore_cool0";
		soc_thermal = "/thermal-zones/soc_thermal";
		pswitch_on = "/thermal-zones/soc_thermal/trips/trip-point@0";
		pcontrol = "/thermal-zones/soc_thermal/trips/trip-point@1";
		phot = "/thermal-zones/soc_thermal/trips/trip-point@2";
		pcritical = "/thermal-zones/soc_thermal/trips/trip-point@3";
		ddr_thermal = "/thermal-zones/ddr_thermal";
		dswitch_on = "/thermal-zones/ddr_thermal/trips/trip-point@0";
		dcontrol = "/thermal-zones/ddr_thermal/trips/trip-point@1";
		dhot = "/thermal-zones/ddr_thermal/trips/trip-point@2";
		dcritical = "/thermal-zones/ddr_thermal/trips/trip-point@3";
		partitions = "/partitions";
		logo = "/partitions/logo";
		recovery = "/partitions/recovery";
		tee = "/partitions/tee";
		factory = "/partitions/factory";
		misc = "/partitions/misc";
		dtbo = "/partitions/dtbo";
		cri_data = "/partitions/cri_data";
		rsv = "/partitions/rsv";
		metadata = "/partitions/metadata";
		vbmeta = "/partitions/vbmeta";
		oem = "/partitions/oem";
		param = "/partitions/param";
		boot = "/partitions/boot";
		super = "/partitions/super";
		cache = "/partitions/cache";
		data = "/partitions/data";
		lcd = "/lcd";
		bl_pwm_conf = "/bl_pwm_conf";
		secmon_reserved = "/reserved-memory/linux,secmon";
		secos_reserved = "/reserved-memory/linux,secos";
		logo_reserved = "/reserved-memory/linux,meson-fb";
		ion_cma_reserved = "/reserved-memory/linux,ion-dev";
		di_cma_reserved = "/reserved-memory/linux,di_cma";
		ppmgr_reserved = "/reserved-memory/linux,ppmgr";
		codec_mm_cma = "/reserved-memory/linux,codec_mm_cma";
		codec_mm_reserved = "/reserved-memory/linux,codec_mm_reserved";
		vdin1_cma_reserved = "/reserved-memory/linux,vdin1_cma";
		vm0_cma_reserved = "/reserved-memory/linux,vm0_cma";
		amlogic_battery = "/dummy-battery";
		amlogic_charger = "/dummy-charger";
		wifi_pwm_conf = "/wifi_pwm_conf";
		picdec_cma_reserved = "/linux,picdec";
		dvb = "/dvb";
		keysn_0 = "/unifykey/key_0";
		keysn_1 = "/unifykey/key_1";
		keysn_2 = "/unifykey/key_2";
		keysn_3 = "/unifykey/key_3";
		keysn_4 = "/unifykey/key_4";
		keysn_5 = "/unifykey/key_5";
		keysn_6 = "/unifykey/key_6";
		keysn_7 = "/unifykey/key_7";
		keysn_8 = "/unifykey/key_8";
		keysn_9 = "/unifykey/key_9";
		keysn_10 = "/unifykey/key_10";
		keysn_11 = "/unifykey/key_11";
		keysn_12 = "/unifykey/key_12";
		keysn_13 = "/unifykey/key_13";
		keysn_14 = "/unifykey/key_14";
		keysn_15 = "/unifykey/key_15";
		keysn_16 = "/unifykey/key_16";
		keysn_17 = "/unifykey/key_17";
		keysn_18 = "/unifykey/key_18";
		keysn_19 = "/unifykey/key_19";
		keysn_20 = "/unifykey/key_20";
		keysn_21 = "/unifykey/key_21";
		keysn_22 = "/unifykey/key_22";
		keysn_23 = "/unifykey/key_23";
		keysn_24 = "/unifykey/key_24";
		keysn_25 = "/unifykey/key_25";
		keysn_26 = "/unifykey/key_26";
		keysn_27 = "/unifykey/key_27";
		keysn_28 = "/unifykey/key_28";
		keysn_29 = "/unifykey/key_29";
		keysn_30 = "/unifykey/key_30";
		keysn_31 = "/unifykey/key_31";
		keysn_32 = "/unifykey/key_32";
		keysn_33 = "/unifykey/key_33";
		keysn_34 = "/unifykey/key_34";
		keysn_35 = "/unifykey/key_35";
		keysn_36 = "/unifykey/key_36";
		keysn_37 = "/unifykey/key_37";
		keysn_38 = "/unifykey/key_38";
		keysn_39 = "/unifykey/key_39";
		keysn_40 = "/unifykey/key_40";
		keysn_41 = "/unifykey/key_41";
		keysn_42 = "/unifykey/key_42";
		keysn_43 = "/unifykey/key_43";
		keysn_44 = "/unifykey/key_44";
		efusekey = "/efusekey";
		key_0 = "/efusekey/key_0";
		key_1 = "/efusekey/key_1";
		key_2 = "/efusekey/key_2";
		key_3 = "/efusekey/key_3";
		dummy_codec = "/dummy";
		pdm_codec = "/dummy";
		amlogic_codec = "/t9015";
		audio_effect = "/eqdrc";
		tdmacpu = "/auge_sound/aml-audio-card,dai-link@0/cpu";
		tdmacodec = "/auge_sound/aml-audio-card,dai-link@0/codec";
		tdmbcodec = "/auge_sound/aml-audio-card,dai-link@1/codec";
		tdmccodec = "/auge_sound/aml-audio-card,dai-link@2/codec";
		audiolocker = "/locker";
		cpu_opp_table0 = "/cpu_opp_table0";
	};
};
